VERSION ""

NS_ :

BS_:

BU_: GW OBD

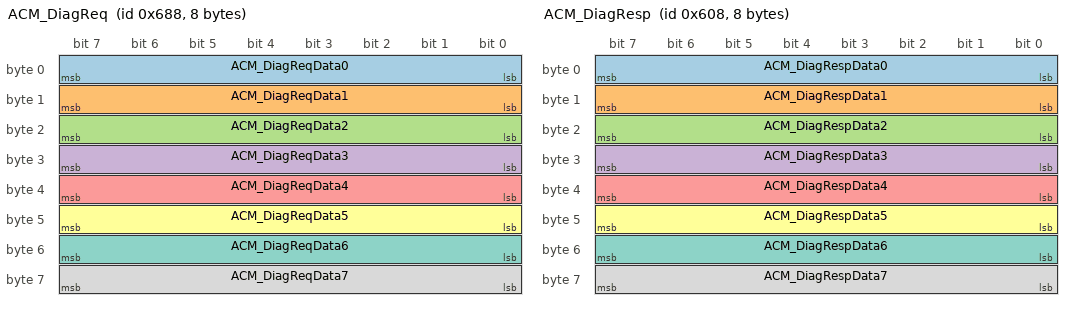
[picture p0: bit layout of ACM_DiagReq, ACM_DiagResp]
BO_ 1672 ACM_DiagReq: 8 OBD
 SG_ ACM_DiagReqData0 : 7|8@0+ (1,0) [0|255] "" GW
 SG_ ACM_DiagReqData1 : 15|8@0+ (1,0) [0|255] "" GW
 SG_ ACM_DiagReqData2 : 23|8@0+ (1,0) [0|255] "" GW
 SG_ ACM_DiagReqData3 : 31|8@0+ (1,0) [0|255] "" GW
 SG_ ACM_DiagReqData4 : 39|8@0+ (1,0) [0|255] "" GW
 SG_ ACM_DiagReqData5 : 47|8@0+ (1,0) [0|255] "" GW
 SG_ ACM_DiagReqData6 : 55|8@0+ (1,0) [0|255] "" GW
 SG_ ACM_DiagReqData7 : 63|8@0+ (1,0) [0|255] "" GW
BO_ 1544 ACM_DiagResp: 8 GW
 SG_ ACM_DiagRespData0 : 7|8@0+ (1,0) [0|255] "" OBD
 SG_ ACM_DiagRespData1 : 15|8@0+ (1,0) [0|255] "" OBD
 SG_ ACM_DiagRespData2 : 23|8@0+ (1,0) [0|255] "" OBD
 SG_ ACM_DiagRespData3 : 31|8@0+ (1,0) [0|255] "" OBD
 SG_ ACM_DiagRespData4 : 39|8@0+ (1,0) [0|255] "" OBD
 SG_ ACM_DiagRespData5 : 47|8@0+ (1,0) [0|255] "" OBD
 SG_ ACM_DiagRespData6 : 55|8@0+ (1,0) [0|255] "" OBD
 SG_ ACM_DiagRespData7 : 63|8@0+ (1,0) [0|255] "" OBD
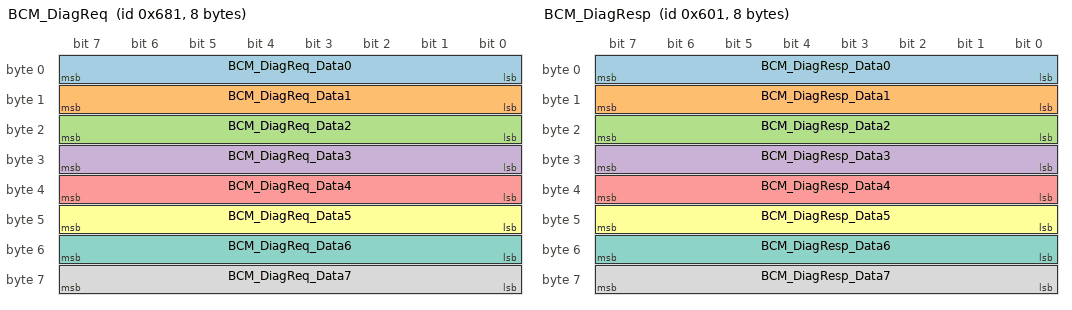
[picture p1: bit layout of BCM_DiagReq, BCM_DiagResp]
BO_ 1665 BCM_DiagReq: 8 OBD
 SG_ BCM_DiagReq_Data0 : 7|8@0+ (1,0) [0|255] "" GW
 SG_ BCM_DiagReq_Data1 : 15|8@0+ (1,0) [0|255] "" GW
 SG_ BCM_DiagReq_Data2 : 23|8@0+ (1,0) [0|255] "" GW
 SG_ BCM_DiagReq_Data3 : 31|8@0+ (1,0) [0|255] "" GW
 SG_ BCM_DiagReq_Data4 : 39|8@0+ (1,0) [0|255] "" GW
 SG_ BCM_DiagReq_Data5 : 47|8@0+ (1,0) [0|255] "" GW
 SG_ BCM_DiagReq_Data6 : 55|8@0+ (1,0) [0|255] "" GW
 SG_ BCM_DiagReq_Data7 : 63|8@0+ (1,0) [0|255] "" GW
BO_ 1537 BCM_DiagResp: 8 GW
 SG_ BCM_DiagResp_Data0 : 7|8@0+ (1,0) [0|255] "" OBD
 SG_ BCM_DiagResp_Data1 : 15|8@0+ (1,0) [0|255] "" OBD
 SG_ BCM_DiagResp_Data2 : 23|8@0+ (1,0) [0|255] "" OBD
 SG_ BCM_DiagResp_Data3 : 31|8@0+ (1,0) [0|255] "" OBD
 SG_ BCM_DiagResp_Data4 : 39|8@0+ (1,0) [0|255] "" OBD
 SG_ BCM_DiagResp_Data5 : 47|8@0+ (1,0) [0|255] "" OBD
 SG_ BCM_DiagResp_Data6 : 55|8@0+ (1,0) [0|255] "" OBD
 SG_ BCM_DiagResp_Data7 : 63|8@0+ (1,0) [0|255] "" OBD
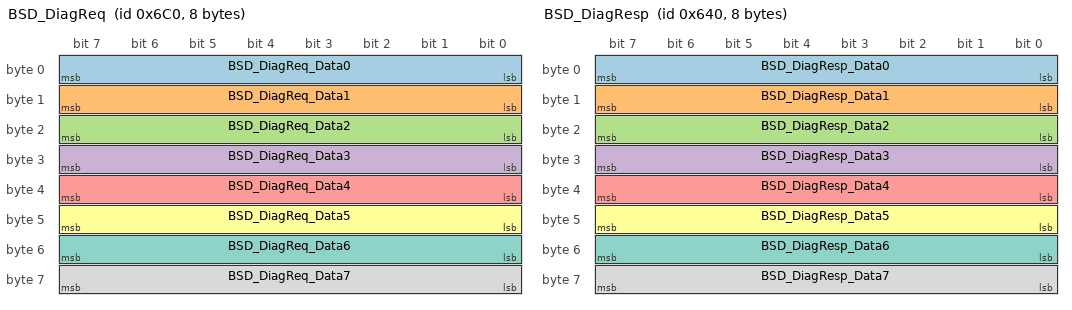
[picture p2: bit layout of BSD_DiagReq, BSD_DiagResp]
BO_ 1728 BSD_DiagReq: 8 OBD
 SG_ BSD_DiagReq_Data0 : 7|8@0+ (1,0) [0|255] "" GW
 SG_ BSD_DiagReq_Data1 : 15|8@0+ (1,0) [0|255] "" GW
 SG_ BSD_DiagReq_Data2 : 23|8@0+ (1,0) [0|255] "" GW
 SG_ BSD_DiagReq_Data3 : 31|8@0+ (1,0) [0|255] "" GW
 SG_ BSD_DiagReq_Data4 : 39|8@0+ (1,0) [0|255] "" GW
 SG_ BSD_DiagReq_Data5 : 47|8@0+ (1,0) [0|255] "" GW
 SG_ BSD_DiagReq_Data6 : 55|8@0+ (1,0) [0|255] "" GW
 SG_ BSD_DiagReq_Data7 : 63|8@0+ (1,0) [0|255] "" GW
BO_ 1600 BSD_DiagResp: 8 GW
 SG_ BSD_DiagResp_Data0 : 7|8@0+ (1,0) [0|255] "" OBD
 SG_ BSD_DiagResp_Data1 : 15|8@0+ (1,0) [0|255] "" OBD
 SG_ BSD_DiagResp_Data2 : 23|8@0+ (1,0) [0|255] "" OBD
 SG_ BSD_DiagResp_Data3 : 31|8@0+ (1,0) [0|255] "" OBD
 SG_ BSD_DiagResp_Data4 : 39|8@0+ (1,0) [0|255] "" OBD
 SG_ BSD_DiagResp_Data5 : 47|8@0+ (1,0) [0|255] "" OBD
 SG_ BSD_DiagResp_Data6 : 55|8@0+ (1,0) [0|255] "" OBD
 SG_ BSD_DiagResp_Data7 : 63|8@0+ (1,0) [0|255] "" OBD
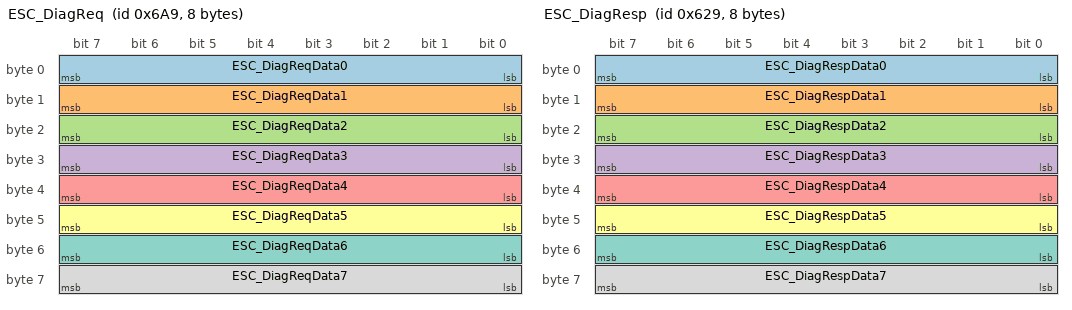
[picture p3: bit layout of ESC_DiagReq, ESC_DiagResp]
BO_ 1705 ESC_DiagReq: 8 OBD
 SG_ ESC_DiagReqData0 : 7|8@0+ (1,0) [0|255] "" GW
 SG_ ESC_DiagReqData1 : 15|8@0+ (1,0) [0|255] "" GW
 SG_ ESC_DiagReqData2 : 23|8@0+ (1,0) [0|255] "" GW
 SG_ ESC_DiagReqData3 : 31|8@0+ (1,0) [0|255] "" GW
 SG_ ESC_DiagReqData4 : 39|8@0+ (1,0) [0|255] "" GW
 SG_ ESC_DiagReqData5 : 47|8@0+ (1,0) [0|255] "" GW
 SG_ ESC_DiagReqData6 : 55|8@0+ (1,0) [0|255] "" GW
 SG_ ESC_DiagReqData7 : 63|8@0+ (1,0) [0|255] "" GW
BO_ 1577 ESC_DiagResp: 8 GW
 SG_ ESC_DiagRespData0 : 7|8@0+ (1,0) [0|255] "" OBD
 SG_ ESC_DiagRespData1 : 15|8@0+ (1,0) [0|255] "" OBD
 SG_ ESC_DiagRespData2 : 23|8@0+ (1,0) [0|255] "" OBD
 SG_ ESC_DiagRespData3 : 31|8@0+ (1,0) [0|255] "" OBD
 SG_ ESC_DiagRespData4 : 39|8@0+ (1,0) [0|255] "" OBD
 SG_ ESC_DiagRespData5 : 47|8@0+ (1,0) [0|255] "" OBD
 SG_ ESC_DiagRespData6 : 55|8@0+ (1,0) [0|255] "" OBD
 SG_ ESC_DiagRespData7 : 63|8@0+ (1,0) [0|255] "" OBD
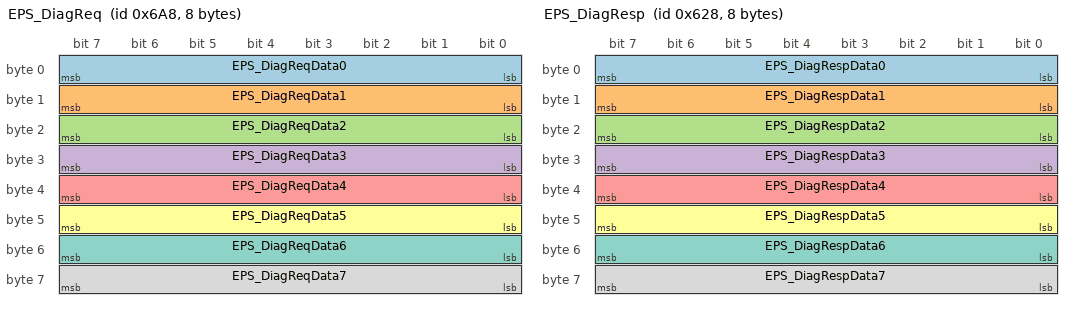
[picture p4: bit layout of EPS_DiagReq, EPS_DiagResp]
BO_ 1704 EPS_DiagReq: 8 OBD
 SG_ EPS_DiagReqData0 : 7|8@0+ (1,0) [0|255] "" GW
 SG_ EPS_DiagReqData1 : 15|8@0+ (1,0) [0|255] "" GW
 SG_ EPS_DiagReqData2 : 23|8@0+ (1,0) [0|255] "" GW
 SG_ EPS_DiagReqData3 : 31|8@0+ (1,0) [0|255] "" GW
 SG_ EPS_DiagReqData4 : 39|8@0+ (1,0) [0|255] "" GW
 SG_ EPS_DiagReqData5 : 47|8@0+ (1,0) [0|255] "" GW
 SG_ EPS_DiagReqData6 : 55|8@0+ (1,0) [0|255] "" GW
 SG_ EPS_DiagReqData7 : 63|8@0+ (1,0) [0|255] "" GW
BO_ 1576 EPS_DiagResp: 8 GW
 SG_ EPS_DiagRespData0 : 7|8@0+ (1,0) [0|255] "" OBD
 SG_ EPS_DiagRespData1 : 15|8@0+ (1,0) [0|255] "" OBD
 SG_ EPS_DiagRespData2 : 23|8@0+ (1,0) [0|255] "" OBD
 SG_ EPS_DiagRespData3 : 31|8@0+ (1,0) [0|255] "" OBD
 SG_ EPS_DiagRespData4 : 39|8@0+ (1,0) [0|255] "" OBD
 SG_ EPS_DiagRespData5 : 47|8@0+ (1,0) [0|255] "" OBD
 SG_ EPS_DiagRespData6 : 55|8@0+ (1,0) [0|255] "" OBD
 SG_ EPS_DiagRespData7 : 63|8@0+ (1,0) [0|255] "" OBD
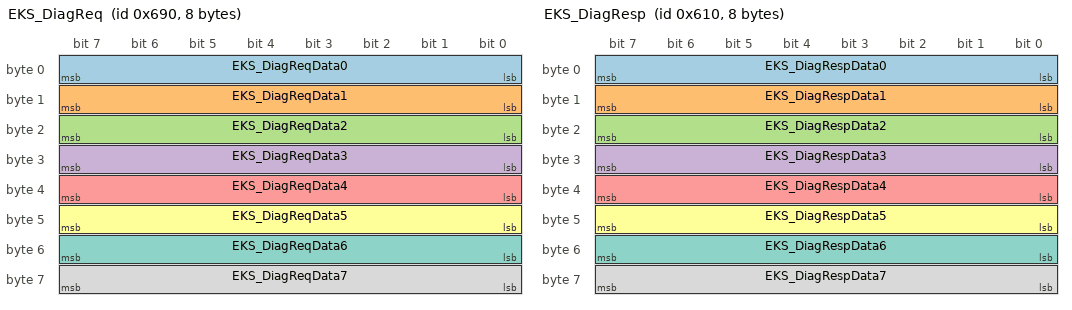
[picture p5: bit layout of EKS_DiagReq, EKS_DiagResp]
BO_ 1680 EKS_DiagReq: 8 OBD
 SG_ EKS_DiagReqData0 : 7|8@0+ (1,0) [0|255] "" GW
 SG_ EKS_DiagReqData1 : 15|8@0+ (1,0) [0|255] "" GW
 SG_ EKS_DiagReqData2 : 23|8@0+ (1,0) [0|255] "" GW
 SG_ EKS_DiagReqData3 : 31|8@0+ (1,0) [0|255] "" GW
 SG_ EKS_DiagReqData4 : 39|8@0+ (1,0) [0|255] "" GW
 SG_ EKS_DiagReqData5 : 47|8@0+ (1,0) [0|255] "" GW
 SG_ EKS_DiagReqData6 : 55|8@0+ (1,0) [0|255] "" GW
 SG_ EKS_DiagReqData7 : 63|8@0+ (1,0) [0|255] "" GW
BO_ 1552 EKS_DiagResp: 8 GW
 SG_ EKS_DiagRespData0 : 7|8@0+ (1,0) [0|255] "" OBD
 SG_ EKS_DiagRespData1 : 15|8@0+ (1,0) [0|255] "" OBD
 SG_ EKS_DiagRespData2 : 23|8@0+ (1,0) [0|255] "" OBD
 SG_ EKS_DiagRespData3 : 31|8@0+ (1,0) [0|255] "" OBD
 SG_ EKS_DiagRespData4 : 39|8@0+ (1,0) [0|255] "" OBD
 SG_ EKS_DiagRespData5 : 47|8@0+ (1,0) [0|255] "" OBD
 SG_ EKS_DiagRespData6 : 55|8@0+ (1,0) [0|255] "" OBD
 SG_ EKS_DiagRespData7 : 63|8@0+ (1,0) [0|255] "" OBD
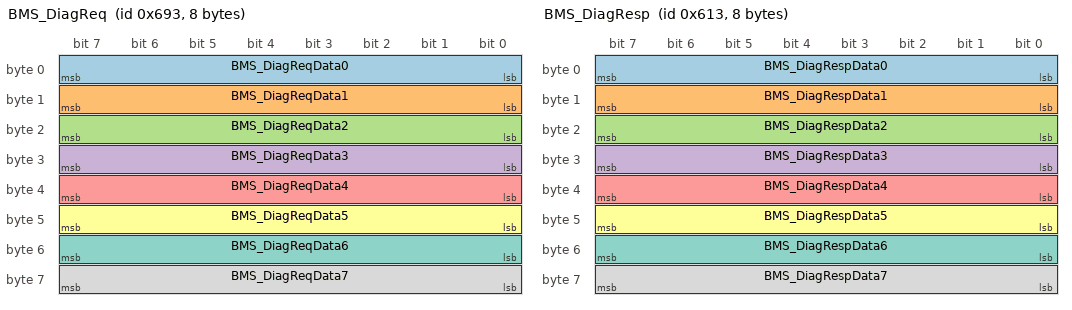
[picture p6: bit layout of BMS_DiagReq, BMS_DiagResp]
BO_ 1683 BMS_DiagReq: 8 OBD
 SG_ BMS_DiagReqData0 : 7|8@0+ (1,0) [0|255] "" GW
 SG_ BMS_DiagReqData1 : 15|8@0+ (1,0) [0|255] "" GW
 SG_ BMS_DiagReqData2 : 23|8@0+ (1,0) [0|255] "" GW
 SG_ BMS_DiagReqData3 : 31|8@0+ (1,0) [0|255] "" GW
 SG_ BMS_DiagReqData4 : 39|8@0+ (1,0) [0|255] "" GW
 SG_ BMS_DiagReqData5 : 47|8@0+ (1,0) [0|255] "" GW
 SG_ BMS_DiagReqData6 : 55|8@0+ (1,0) [0|255] "" GW
 SG_ BMS_DiagReqData7 : 63|8@0+ (1,0) [0|255] "" GW
BO_ 1555 BMS_DiagResp: 8 GW
 SG_ BMS_DiagRespData0 : 7|8@0+ (1,0) [0|255] "" OBD
 SG_ BMS_DiagRespData1 : 15|8@0+ (1,0) [0|255] "" OBD
 SG_ BMS_DiagRespData2 : 23|8@0+ (1,0) [0|255] "" OBD
 SG_ BMS_DiagRespData3 : 31|8@0+ (1,0) [0|255] "" OBD
 SG_ BMS_DiagRespData4 : 39|8@0+ (1,0) [0|255] "" OBD
 SG_ BMS_DiagRespData5 : 47|8@0+ (1,0) [0|255] "" OBD
 SG_ BMS_DiagRespData6 : 55|8@0+ (1,0) [0|255] "" OBD
 SG_ BMS_DiagRespData7 : 63|8@0+ (1,0) [0|255] "" OBD
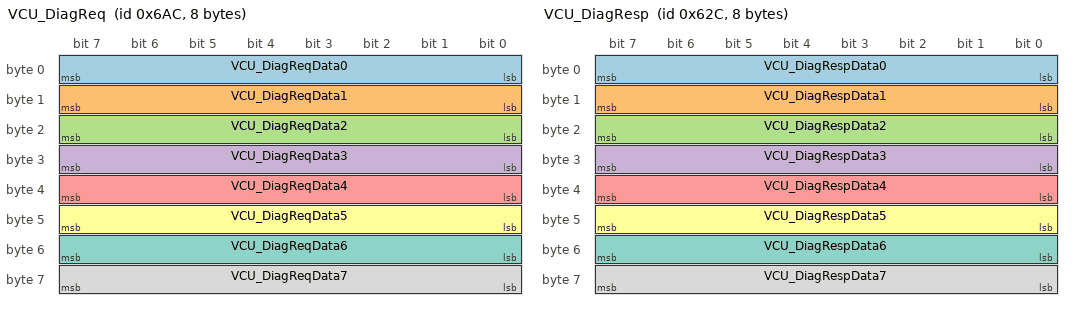
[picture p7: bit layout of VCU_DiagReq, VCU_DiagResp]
BO_ 1708 VCU_DiagReq: 8 OBD
 SG_ VCU_DiagReqData0 : 7|8@0+ (1,0) [0|255] "" GW
 SG_ VCU_DiagReqData1 : 15|8@0+ (1,0) [0|255] "" GW
 SG_ VCU_DiagReqData2 : 23|8@0+ (1,0) [0|255] "" GW
 SG_ VCU_DiagReqData3 : 31|8@0+ (1,0) [0|255] "" GW
 SG_ VCU_DiagReqData4 : 39|8@0+ (1,0) [0|255] "" GW
 SG_ VCU_DiagReqData5 : 47|8@0+ (1,0) [0|255] "" GW
 SG_ VCU_DiagReqData6 : 55|8@0+ (1,0) [0|255] "" GW
 SG_ VCU_DiagReqData7 : 63|8@0+ (1,0) [0|255] "" GW
BO_ 1580 VCU_DiagResp: 8 GW
 SG_ VCU_DiagRespData0 : 7|8@0+ (1,0) [0|255] "" OBD
 SG_ VCU_DiagRespData1 : 15|8@0+ (1,0) [0|255] "" OBD
 SG_ VCU_DiagRespData2 : 23|8@0+ (1,0) [0|255] "" OBD
 SG_ VCU_DiagRespData3 : 31|8@0+ (1,0) [0|255] "" OBD
 SG_ VCU_DiagRespData4 : 39|8@0+ (1,0) [0|255] "" OBD
 SG_ VCU_DiagRespData5 : 47|8@0+ (1,0) [0|255] "" OBD
 SG_ VCU_DiagRespData6 : 55|8@0+ (1,0) [0|255] "" OBD
 SG_ VCU_DiagRespData7 : 63|8@0+ (1,0) [0|255] "" OBD
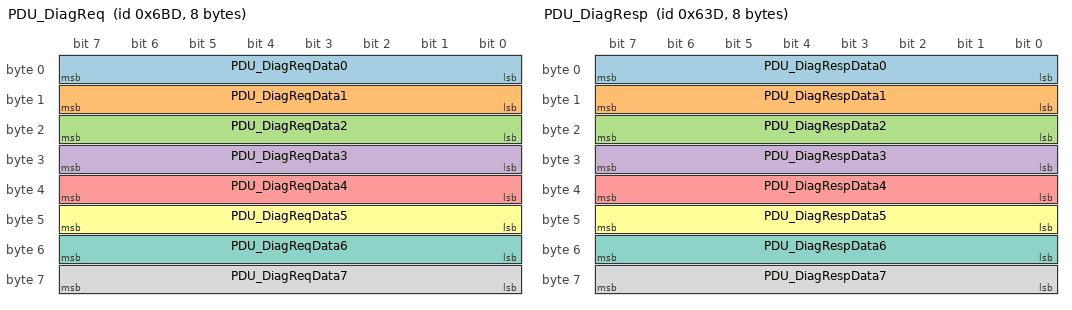
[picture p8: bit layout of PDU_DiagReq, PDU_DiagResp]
BO_ 1725 PDU_DiagReq: 8 OBD
 SG_ PDU_DiagReqData0 : 7|8@0+ (1,0) [0|255] "" GW
 SG_ PDU_DiagReqData1 : 15|8@0+ (1,0) [0|255] "" GW
 SG_ PDU_DiagReqData2 : 23|8@0+ (1,0) [0|255] "" GW
 SG_ PDU_DiagReqData3 : 31|8@0+ (1,0) [0|255] "" GW
 SG_ PDU_DiagReqData4 : 39|8@0+ (1,0) [0|255] "" GW
 SG_ PDU_DiagReqData5 : 47|8@0+ (1,0) [0|255] "" GW
 SG_ PDU_DiagReqData6 : 55|8@0+ (1,0) [0|255] "" GW
 SG_ PDU_DiagReqData7 : 63|8@0+ (1,0) [0|255] "" GW
BO_ 1597 PDU_DiagResp: 8 GW
 SG_ PDU_DiagRespData0 : 7|8@0+ (1,0) [0|255] "" OBD
 SG_ PDU_DiagRespData1 : 15|8@0+ (1,0) [0|255] "" OBD
 SG_ PDU_DiagRespData2 : 23|8@0+ (1,0) [0|255] "" OBD
 SG_ PDU_DiagRespData3 : 31|8@0+ (1,0) [0|255] "" OBD
 SG_ PDU_DiagRespData4 : 39|8@0+ (1,0) [0|255] "" OBD
 SG_ PDU_DiagRespData5 : 47|8@0+ (1,0) [0|255] "" OBD
 SG_ PDU_DiagRespData6 : 55|8@0+ (1,0) [0|255] "" OBD
 SG_ PDU_DiagRespData7 : 63|8@0+ (1,0) [0|255] "" OBD
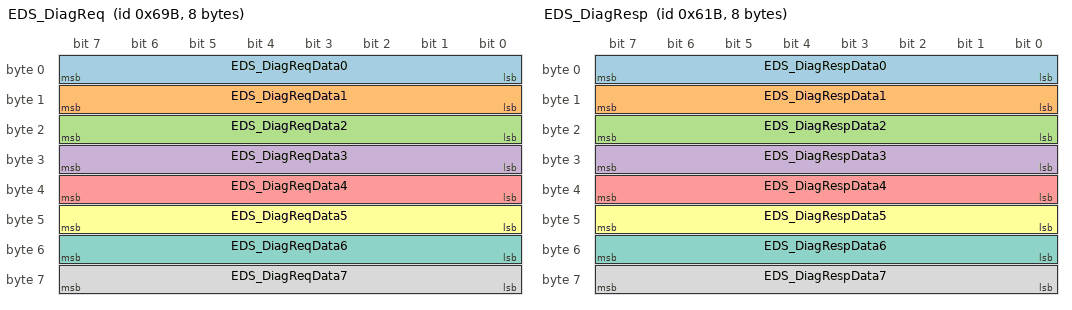
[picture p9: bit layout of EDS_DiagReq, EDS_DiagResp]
BO_ 1691 EDS_DiagReq: 8 OBD
 SG_ EDS_DiagReqData0 : 7|8@0+ (1,0) [0|255] "" GW
 SG_ EDS_DiagReqData1 : 15|8@0+ (1,0) [0|255] "" GW
 SG_ EDS_DiagReqData2 : 23|8@0+ (1,0) [0|255] "" GW
 SG_ EDS_DiagReqData3 : 31|8@0+ (1,0) [0|255] "" GW
 SG_ EDS_DiagReqData4 : 39|8@0+ (1,0) [0|255] "" GW
 SG_ EDS_DiagReqData5 : 47|8@0+ (1,0) [0|255] "" GW
 SG_ EDS_DiagReqData6 : 55|8@0+ (1,0) [0|255] "" GW
 SG_ EDS_DiagReqData7 : 63|8@0+ (1,0) [0|255] "" GW
BO_ 1563 EDS_DiagResp: 8 GW
 SG_ EDS_DiagRespData0 : 7|8@0+ (1,0) [0|255] "" OBD
 SG_ EDS_DiagRespData1 : 15|8@0+ (1,0) [0|255] "" OBD
 SG_ EDS_DiagRespData2 : 23|8@0+ (1,0) [0|255] "" OBD
 SG_ EDS_DiagRespData3 : 31|8@0+ (1,0) [0|255] "" OBD
 SG_ EDS_DiagRespData4 : 39|8@0+ (1,0) [0|255] "" OBD
 SG_ EDS_DiagRespData5 : 47|8@0+ (1,0) [0|255] "" OBD
 SG_ EDS_DiagRespData6 : 55|8@0+ (1,0) [0|255] "" OBD
 SG_ EDS_DiagRespData7 : 63|8@0+ (1,0) [0|255] "" OBD
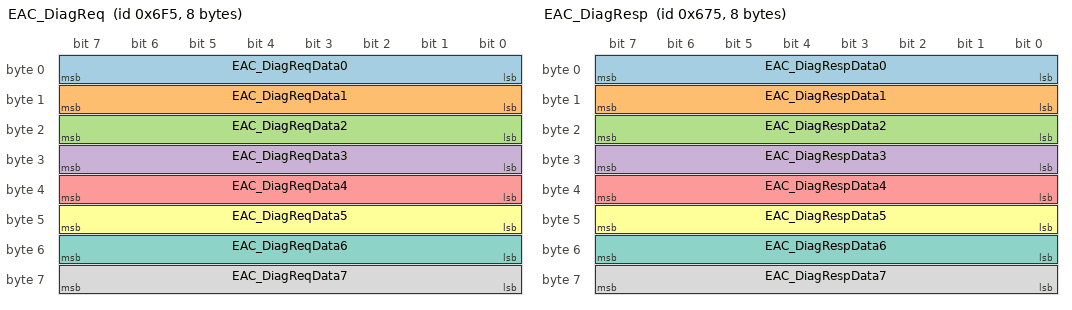
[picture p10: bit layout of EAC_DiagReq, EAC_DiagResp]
BO_ 1781 EAC_DiagReq: 8 OBD
 SG_ EAC_DiagReqData0 : 7|8@0+ (1,0) [0|255] "" GW
 SG_ EAC_DiagReqData1 : 15|8@0+ (1,0) [0|255] "" GW
 SG_ EAC_DiagReqData2 : 23|8@0+ (1,0) [0|255] "" GW
 SG_ EAC_DiagReqData3 : 31|8@0+ (1,0) [0|255] "" GW
 SG_ EAC_DiagReqData4 : 39|8@0+ (1,0) [0|255] "" GW
 SG_ EAC_DiagReqData5 : 47|8@0+ (1,0) [0|255] "" GW
 SG_ EAC_DiagReqData6 : 55|8@0+ (1,0) [0|255] "" GW
 SG_ EAC_DiagReqData7 : 63|8@0+ (1,0) [0|255] "" GW
BO_ 1653 EAC_DiagResp: 8 GW
 SG_ EAC_DiagRespData0 : 7|8@0+ (1,0) [0|255] "" OBD
 SG_ EAC_DiagRespData1 : 15|8@0+ (1,0) [0|255] "" OBD
 SG_ EAC_DiagRespData2 : 23|8@0+ (1,0) [0|255] "" OBD
 SG_ EAC_DiagRespData3 : 31|8@0+ (1,0) [0|255] "" OBD
 SG_ EAC_DiagRespData4 : 39|8@0+ (1,0) [0|255] "" OBD
 SG_ EAC_DiagRespData5 : 47|8@0+ (1,0) [0|255] "" OBD
 SG_ EAC_DiagRespData6 : 55|8@0+ (1,0) [0|255] "" OBD
 SG_ EAC_DiagRespData7 : 63|8@0+ (1,0) [0|255] "" OBD
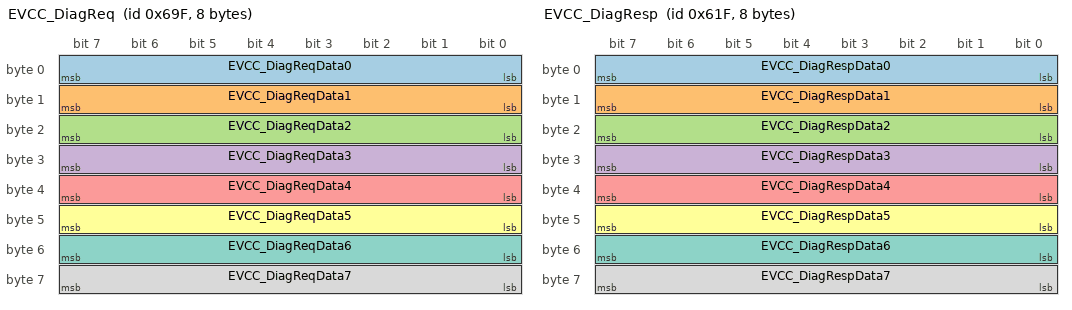
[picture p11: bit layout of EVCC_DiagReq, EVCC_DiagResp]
BO_ 1695 EVCC_DiagReq: 8 OBD
 SG_ EVCC_DiagReqData0 : 7|8@0+ (1,0) [0|255] "" GW
 SG_ EVCC_DiagReqData1 : 15|8@0+ (1,0) [0|255] "" GW
 SG_ EVCC_DiagReqData2 : 23|8@0+ (1,0) [0|255] "" GW
 SG_ EVCC_DiagReqData3 : 31|8@0+ (1,0) [0|255] "" GW
 SG_ EVCC_DiagReqData4 : 39|8@0+ (1,0) [0|255] "" GW
 SG_ EVCC_DiagReqData5 : 47|8@0+ (1,0) [0|255] "" GW
 SG_ EVCC_DiagReqData6 : 55|8@0+ (1,0) [0|255] "" GW
 SG_ EVCC_DiagReqData7 : 63|8@0+ (1,0) [0|255] "" GW
BO_ 1567 EVCC_DiagResp: 8 GW
 SG_ EVCC_DiagRespData0 : 7|8@0+ (1,0) [0|255] "" OBD
 SG_ EVCC_DiagRespData1 : 15|8@0+ (1,0) [0|255] "" OBD
 SG_ EVCC_DiagRespData2 : 23|8@0+ (1,0) [0|255] "" OBD
 SG_ EVCC_DiagRespData3 : 31|8@0+ (1,0) [0|255] "" OBD
 SG_ EVCC_DiagRespData4 : 39|8@0+ (1,0) [0|255] "" OBD
 SG_ EVCC_DiagRespData5 : 47|8@0+ (1,0) [0|255] "" OBD
 SG_ EVCC_DiagRespData6 : 55|8@0+ (1,0) [0|255] "" OBD
 SG_ EVCC_DiagRespData7 : 63|8@0+ (1,0) [0|255] "" OBD
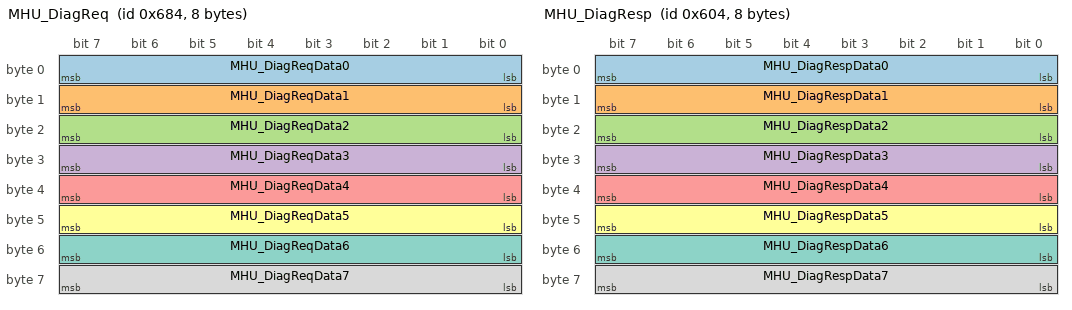
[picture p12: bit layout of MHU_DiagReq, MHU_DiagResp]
BO_ 1668 MHU_DiagReq: 8 OBD
 SG_ MHU_DiagReqData0 : 7|8@0+ (1,0) [0|255] "" GW
 SG_ MHU_DiagReqData1 : 15|8@0+ (1,0) [0|255] "" GW
 SG_ MHU_DiagReqData2 : 23|8@0+ (1,0) [0|255] "" GW
 SG_ MHU_DiagReqData3 : 31|8@0+ (1,0) [0|255] "" GW
 SG_ MHU_DiagReqData4 : 39|8@0+ (1,0) [0|255] "" GW
 SG_ MHU_DiagReqData5 : 47|8@0+ (1,0) [0|255] "" GW
 SG_ MHU_DiagReqData6 : 55|8@0+ (1,0) [0|255] "" GW
 SG_ MHU_DiagReqData7 : 63|8@0+ (1,0) [0|255] "" GW
BO_ 1540 MHU_DiagResp: 8 GW
 SG_ MHU_DiagRespData0 : 7|8@0+ (1,0) [0|255] "" OBD
 SG_ MHU_DiagRespData1 : 15|8@0+ (1,0) [0|255] "" OBD
 SG_ MHU_DiagRespData2 : 23|8@0+ (1,0) [0|255] "" OBD
 SG_ MHU_DiagRespData3 : 31|8@0+ (1,0) [0|255] "" OBD
 SG_ MHU_DiagRespData4 : 39|8@0+ (1,0) [0|255] "" OBD
 SG_ MHU_DiagRespData5 : 47|8@0+ (1,0) [0|255] "" OBD
 SG_ MHU_DiagRespData6 : 55|8@0+ (1,0) [0|255] "" OBD
 SG_ MHU_DiagRespData7 : 63|8@0+ (1,0) [0|255] "" OBD
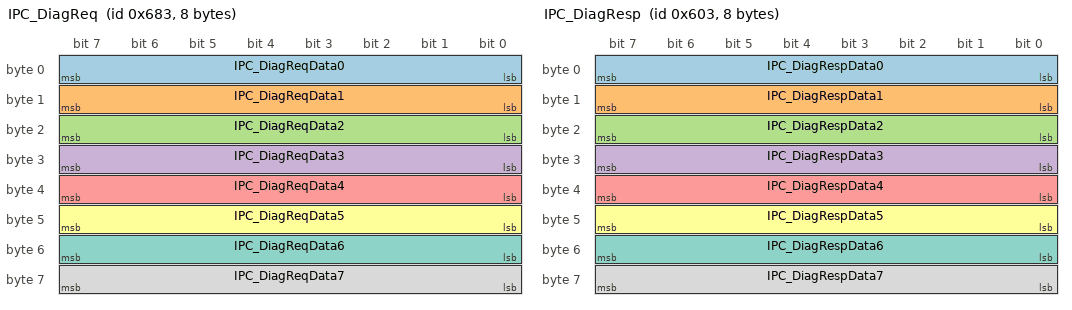
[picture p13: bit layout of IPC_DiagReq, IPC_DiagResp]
BO_ 1667 IPC_DiagReq: 8 OBD
 SG_ IPC_DiagReqData0 : 7|8@0+ (1,0) [0|255] "" GW
 SG_ IPC_DiagReqData1 : 15|8@0+ (1,0) [0|255] "" GW
 SG_ IPC_DiagReqData2 : 23|8@0+ (1,0) [0|255] "" GW
 SG_ IPC_DiagReqData3 : 31|8@0+ (1,0) [0|255] "" GW
 SG_ IPC_DiagReqData4 : 39|8@0+ (1,0) [0|255] "" GW
 SG_ IPC_DiagReqData5 : 47|8@0+ (1,0) [0|255] "" GW
 SG_ IPC_DiagReqData6 : 55|8@0+ (1,0) [0|255] "" GW
 SG_ IPC_DiagReqData7 : 63|8@0+ (1,0) [0|255] "" GW
BO_ 1539 IPC_DiagResp: 8 GW
 SG_ IPC_DiagRespData0 : 7|8@0+ (1,0) [0|255] "" OBD
 SG_ IPC_DiagRespData1 : 15|8@0+ (1,0) [0|255] "" OBD
 SG_ IPC_DiagRespData2 : 23|8@0+ (1,0) [0|255] "" OBD
 SG_ IPC_DiagRespData3 : 31|8@0+ (1,0) [0|255] "" OBD
 SG_ IPC_DiagRespData4 : 39|8@0+ (1,0) [0|255] "" OBD
 SG_ IPC_DiagRespData5 : 47|8@0+ (1,0) [0|255] "" OBD
 SG_ IPC_DiagRespData6 : 55|8@0+ (1,0) [0|255] "" OBD
 SG_ IPC_DiagRespData7 : 63|8@0+ (1,0) [0|255] "" OBD
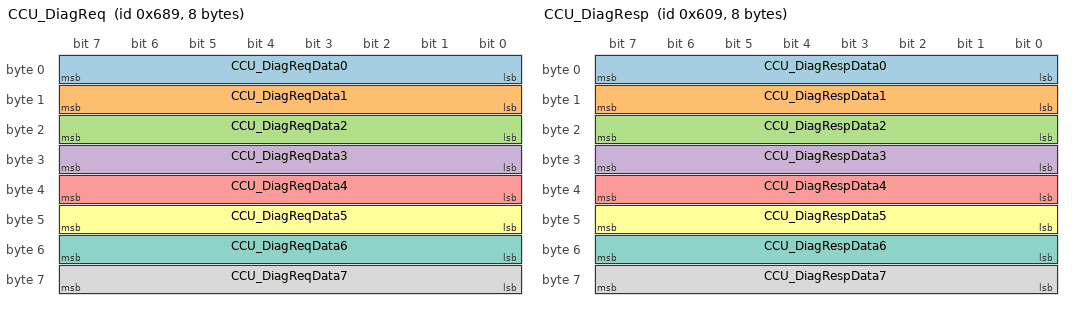
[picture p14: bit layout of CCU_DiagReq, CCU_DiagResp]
BO_ 1673 CCU_DiagReq: 8 OBD
 SG_ CCU_DiagReqData0 : 7|8@0+ (1,0) [0|255] "" GW
 SG_ CCU_DiagReqData1 : 15|8@0+ (1,0) [0|255] "" GW
 SG_ CCU_DiagReqData2 : 23|8@0+ (1,0) [0|255] "" GW
 SG_ CCU_DiagReqData3 : 31|8@0+ (1,0) [0|255] "" GW
 SG_ CCU_DiagReqData4 : 39|8@0+ (1,0) [0|255] "" GW
 SG_ CCU_DiagReqData5 : 47|8@0+ (1,0) [0|255] "" GW
 SG_ CCU_DiagReqData6 : 55|8@0+ (1,0) [0|255] "" GW
 SG_ CCU_DiagReqData7 : 63|8@0+ (1,0) [0|255] "" GW
BO_ 1545 CCU_DiagResp: 8 GW
 SG_ CCU_DiagRespData0 : 7|8@0+ (1,0) [0|255] "" OBD
 SG_ CCU_DiagRespData1 : 15|8@0+ (1,0) [0|255] "" OBD
 SG_ CCU_DiagRespData2 : 23|8@0+ (1,0) [0|255] "" OBD
 SG_ CCU_DiagRespData3 : 31|8@0+ (1,0) [0|255] "" OBD
 SG_ CCU_DiagRespData4 : 39|8@0+ (1,0) [0|255] "" OBD
 SG_ CCU_DiagRespData5 : 47|8@0+ (1,0) [0|255] "" OBD
 SG_ CCU_DiagRespData6 : 55|8@0+ (1,0) [0|255] "" OBD
 SG_ CCU_DiagRespData7 : 63|8@0+ (1,0) [0|255] "" OBD
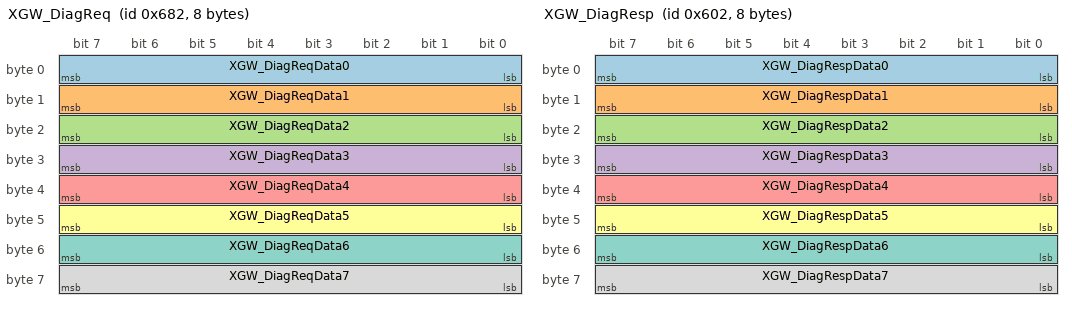
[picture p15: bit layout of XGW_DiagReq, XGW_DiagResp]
BO_ 1666 XGW_DiagReq: 8 OBD
 SG_ XGW_DiagReqData0 : 7|8@0+ (1,0) [0|255] "" GW
 SG_ XGW_DiagReqData1 : 15|8@0+ (1,0) [0|255] "" GW
 SG_ XGW_DiagReqData2 : 23|8@0+ (1,0) [0|255] "" GW
 SG_ XGW_DiagReqData3 : 31|8@0+ (1,0) [0|255] "" GW
 SG_ XGW_DiagReqData4 : 39|8@0+ (1,0) [0|255] "" GW
 SG_ XGW_DiagReqData5 : 47|8@0+ (1,0) [0|255] "" GW
 SG_ XGW_DiagReqData6 : 55|8@0+ (1,0) [0|255] "" GW
 SG_ XGW_DiagReqData7 : 63|8@0+ (1,0) [0|255] "" GW
BO_ 1538 XGW_DiagResp: 8 GW
 SG_ XGW_DiagRespData0 : 7|8@0+ (1,0) [0|255] "" OBD
 SG_ XGW_DiagRespData1 : 15|8@0+ (1,0) [0|255] "" OBD
 SG_ XGW_DiagRespData2 : 23|8@0+ (1,0) [0|255] "" OBD
 SG_ XGW_DiagRespData3 : 31|8@0+ (1,0) [0|255] "" OBD
 SG_ XGW_DiagRespData4 : 39|8@0+ (1,0) [0|255] "" OBD
 SG_ XGW_DiagRespData5 : 47|8@0+ (1,0) [0|255] "" OBD
 SG_ XGW_DiagRespData6 : 55|8@0+ (1,0) [0|255] "" OBD
 SG_ XGW_DiagRespData7 : 63|8@0+ (1,0) [0|255] "" OBD
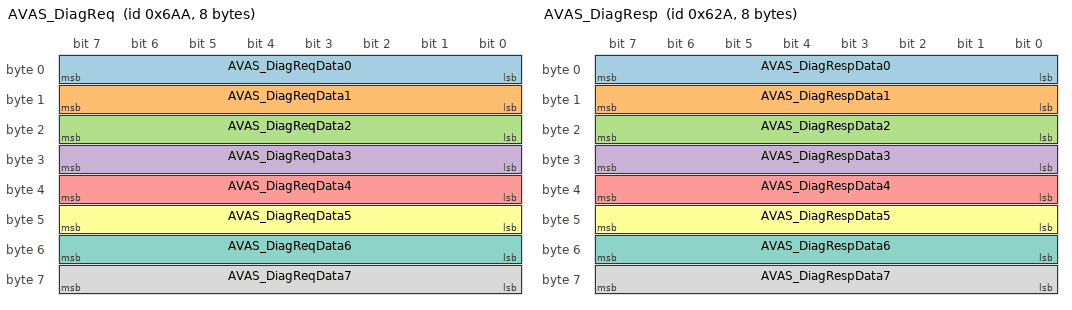
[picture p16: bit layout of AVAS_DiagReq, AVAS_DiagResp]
BO_ 1706 AVAS_DiagReq: 8 OBD
 SG_ AVAS_DiagReqData0 : 7|8@0+ (1,0) [0|255] "" GW
 SG_ AVAS_DiagReqData1 : 15|8@0+ (1,0) [0|255] "" GW
 SG_ AVAS_DiagReqData2 : 23|8@0+ (1,0) [0|255] "" GW
 SG_ AVAS_DiagReqData3 : 31|8@0+ (1,0) [0|255] "" GW
 SG_ AVAS_DiagReqData4 : 39|8@0+ (1,0) [0|255] "" GW
 SG_ AVAS_DiagReqData5 : 47|8@0+ (1,0) [0|255] "" GW
 SG_ AVAS_DiagReqData6 : 55|8@0+ (1,0) [0|255] "" GW
 SG_ AVAS_DiagReqData7 : 63|8@0+ (1,0) [0|255] "" GW
BO_ 1578 AVAS_DiagResp: 8 GW
 SG_ AVAS_DiagRespData0 : 7|8@0+ (1,0) [0|255] "" OBD
 SG_ AVAS_DiagRespData1 : 15|8@0+ (1,0) [0|255] "" OBD
 SG_ AVAS_DiagRespData2 : 23|8@0+ (1,0) [0|255] "" OBD
 SG_ AVAS_DiagRespData3 : 31|8@0+ (1,0) [0|255] "" OBD
 SG_ AVAS_DiagRespData4 : 39|8@0+ (1,0) [0|255] "" OBD
 SG_ AVAS_DiagRespData5 : 47|8@0+ (1,0) [0|255] "" OBD
 SG_ AVAS_DiagRespData6 : 55|8@0+ (1,0) [0|255] "" OBD
 SG_ AVAS_DiagRespData7 : 63|8@0+ (1,0) [0|255] "" OBD
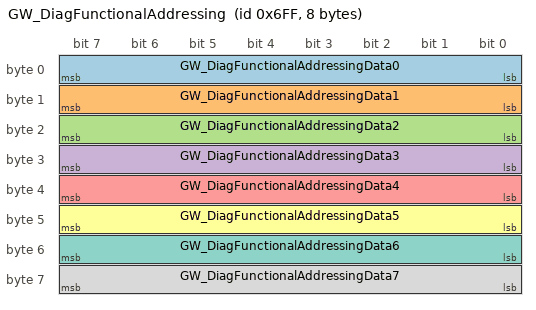
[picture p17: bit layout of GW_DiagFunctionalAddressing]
BO_ 1791 GW_DiagFunctionalAddressing: 8 OBD
 SG_ GW_DiagFunctionalAddressingData0 : 7|8@0+ (1,0) [0|255] "" GW
 SG_ GW_DiagFunctionalAddressingData1 : 15|8@0+ (1,0) [0|255] "" GW
 SG_ GW_DiagFunctionalAddressingData2 : 23|8@0+ (1,0) [0|255] "" GW
 SG_ GW_DiagFunctionalAddressingData3 : 31|8@0+ (1,0) [0|255] "" GW
 SG_ GW_DiagFunctionalAddressingData4 : 39|8@0+ (1,0) [0|255] "" GW
 SG_ GW_DiagFunctionalAddressingData5 : 47|8@0+ (1,0) [0|255] "" GW
 SG_ GW_DiagFunctionalAddressingData6 : 55|8@0+ (1,0) [0|255] "" GW
 SG_ GW_DiagFunctionalAddressingData7 : 63|8@0+ (1,0) [0|255] "" GW
CM_ SG_ 1672 ACM_DiagReqData0 "Data0";
CM_ SG_ 1672 ACM_DiagReqData1 "Data1";
CM_ SG_ 1672 ACM_DiagReqData2 "Data2";
CM_ SG_ 1672 ACM_DiagReqData3 "Data3";
CM_ SG_ 1672 ACM_DiagReqData4 "Data4";
CM_ SG_ 1672 ACM_DiagReqData5 "Data5";
CM_ SG_ 1672 ACM_DiagReqData6 "Data6";
CM_ SG_ 1672 ACM_DiagReqData7 "Data7";
CM_ SG_ 1544 ACM_DiagRespData0 "Data0";
CM_ SG_ 1544 ACM_DiagRespData1 "Data1";
CM_ SG_ 1544 ACM_DiagRespData2 "Data2";
CM_ SG_ 1544 ACM_DiagRespData3 "Data3";
CM_ SG_ 1544 ACM_DiagRespData4 "Data4";
CM_ SG_ 1544 ACM_DiagRespData5 "Data5";
CM_ SG_ 1544 ACM_DiagRespData6 "Data6";
CM_ SG_ 1544 ACM_DiagRespData7 "Data7";
CM_ SG_ 1665 BCM_DiagReq_Data0 "Data0";
CM_ SG_ 1665 BCM_DiagReq_Data1 "Data1";
CM_ SG_ 1665 BCM_DiagReq_Data2 "Data2";
CM_ SG_ 1665 BCM_DiagReq_Data3 "Data3";
CM_ SG_ 1665 BCM_DiagReq_Data4 "Data4";
CM_ SG_ 1665 BCM_DiagReq_Data5 "Data5";
CM_ SG_ 1665 BCM_DiagReq_Data6 "Data6";
CM_ SG_ 1665 BCM_DiagReq_Data7 "Data7";
CM_ SG_ 1537 BCM_DiagResp_Data0 "Data0";
CM_ SG_ 1537 BCM_DiagResp_Data1 "Data1";
CM_ SG_ 1537 BCM_DiagResp_Data2 "Data2";
CM_ SG_ 1537 BCM_DiagResp_Data3 "Data3";
CM_ SG_ 1537 BCM_DiagResp_Data4 "Data4";
CM_ SG_ 1537 BCM_DiagResp_Data5 "Data5";
CM_ SG_ 1537 BCM_DiagResp_Data6 "Data6";
CM_ SG_ 1537 BCM_DiagResp_Data7 "Data7";
CM_ SG_ 1728 BSD_DiagReq_Data0 "Data0";
CM_ SG_ 1728 BSD_DiagReq_Data1 "Data1";
CM_ SG_ 1728 BSD_DiagReq_Data2 "Data2";
CM_ SG_ 1728 BSD_DiagReq_Data3 "Data3";
CM_ SG_ 1728 BSD_DiagReq_Data4 "Data4";
CM_ SG_ 1728 BSD_DiagReq_Data5 "Data5";
CM_ SG_ 1728 BSD_DiagReq_Data6 "Data6";
CM_ SG_ 1728 BSD_DiagReq_Data7 "Data7";
CM_ SG_ 1600 BSD_DiagResp_Data0 "Data0";
CM_ SG_ 1600 BSD_DiagResp_Data1 "Data1";
CM_ SG_ 1600 BSD_DiagResp_Data2 "Data2";
CM_ SG_ 1600 BSD_DiagResp_Data3 "Data3";
CM_ SG_ 1600 BSD_DiagResp_Data4 "Data4";
CM_ SG_ 1600 BSD_DiagResp_Data5 "Data5";
CM_ SG_ 1600 BSD_DiagResp_Data6 "Data6";
CM_ SG_ 1600 BSD_DiagResp_Data7 "Data7";
CM_ SG_ 1705 ESC_DiagReqData0 "Data0";
CM_ SG_ 1705 ESC_DiagReqData1 "Data1";
CM_ SG_ 1705 ESC_DiagReqData2 "Data2";
CM_ SG_ 1705 ESC_DiagReqData3 "Data3";
CM_ SG_ 1705 ESC_DiagReqData4 "Data4";
CM_ SG_ 1705 ESC_DiagReqData5 "Data5";
CM_ SG_ 1705 ESC_DiagReqData6 "Data6";
CM_ SG_ 1705 ESC_DiagReqData7 "Data7";
CM_ SG_ 1577 ESC_DiagRespData0 "Data0";
CM_ SG_ 1577 ESC_DiagRespData1 "Data1";
CM_ SG_ 1577 ESC_DiagRespData2 "Data2";
CM_ SG_ 1577 ESC_DiagRespData3 "Data3";
CM_ SG_ 1577 ESC_DiagRespData4 "Data4";
CM_ SG_ 1577 ESC_DiagRespData5 "Data5";
CM_ SG_ 1577 ESC_DiagRespData6 "Data6";
CM_ SG_ 1577 ESC_DiagRespData7 "Data7";
CM_ SG_ 1704 EPS_DiagReqData0 "Data0";
CM_ SG_ 1704 EPS_DiagReqData1 "Data1";
CM_ SG_ 1704 EPS_DiagReqData2 "Data2";
CM_ SG_ 1704 EPS_DiagReqData3 "Data3";
CM_ SG_ 1704 EPS_DiagReqData4 "Data4";
CM_ SG_ 1704 EPS_DiagReqData5 "Data5";
CM_ SG_ 1704 EPS_DiagReqData6 "Data6";
CM_ SG_ 1704 EPS_DiagReqData7 "Data7";
CM_ SG_ 1576 EPS_DiagRespData0 "Data0";
CM_ SG_ 1576 EPS_DiagRespData1 "Data1";
CM_ SG_ 1576 EPS_DiagRespData2 "Data2";
CM_ SG_ 1576 EPS_DiagRespData3 "Data3";
CM_ SG_ 1576 EPS_DiagRespData4 "Data4";
CM_ SG_ 1576 EPS_DiagRespData5 "Data5";
CM_ SG_ 1576 EPS_DiagRespData6 "Data6";
CM_ SG_ 1576 EPS_DiagRespData7 "Data7";
CM_ SG_ 1680 EKS_DiagReqData0 "Data0";
CM_ SG_ 1680 EKS_DiagReqData1 "Data1";
CM_ SG_ 1680 EKS_DiagReqData2 "Data2";
CM_ SG_ 1680 EKS_DiagReqData3 "Data3";
CM_ SG_ 1680 EKS_DiagReqData4 "Data4";
CM_ SG_ 1680 EKS_DiagReqData5 "Data5";
CM_ SG_ 1680 EKS_DiagReqData6 "Data6";
CM_ SG_ 1680 EKS_DiagReqData7 "Data7";
CM_ SG_ 1552 EKS_DiagRespData0 "Data0";
CM_ SG_ 1552 EKS_DiagRespData1 "Data1";
CM_ SG_ 1552 EKS_DiagRespData2 "Data2";
CM_ SG_ 1552 EKS_DiagRespData3 "Data3";
CM_ SG_ 1552 EKS_DiagRespData4 "Data4";
CM_ SG_ 1552 EKS_DiagRespData5 "Data5";
CM_ SG_ 1552 EKS_DiagRespData6 "Data6";
CM_ SG_ 1552 EKS_DiagRespData7 "Data7";
CM_ SG_ 1683 BMS_DiagReqData0 "Data0";
CM_ SG_ 1683 BMS_DiagReqData1 "Data1";
CM_ SG_ 1683 BMS_DiagReqData2 "Data2";
CM_ SG_ 1683 BMS_DiagReqData3 "Data3";
CM_ SG_ 1683 BMS_DiagReqData4 "Data4";
CM_ SG_ 1683 BMS_DiagReqData5 "Data5";
CM_ SG_ 1683 BMS_DiagReqData6 "Data6";
CM_ SG_ 1683 BMS_DiagReqData7 "Data7";
CM_ SG_ 1555 BMS_DiagRespData0 "Data0";
CM_ SG_ 1555 BMS_DiagRespData1 "Data1";
CM_ SG_ 1555 BMS_DiagRespData2 "Data2";
CM_ SG_ 1555 BMS_DiagRespData3 "Data3";
CM_ SG_ 1555 BMS_DiagRespData4 "Data4";
CM_ SG_ 1555 BMS_DiagRespData5 "Data5";
CM_ SG_ 1555 BMS_DiagRespData6 "Data6";
CM_ SG_ 1555 BMS_DiagRespData7 "Data7";
CM_ SG_ 1708 VCU_DiagReqData0 "Data0";
CM_ SG_ 1708 VCU_DiagReqData1 "Data1";
CM_ SG_ 1708 VCU_DiagReqData2 "Data2";
CM_ SG_ 1708 VCU_DiagReqData3 "Data3";
CM_ SG_ 1708 VCU_DiagReqData4 "Data4";
CM_ SG_ 1708 VCU_DiagReqData5 "Data5";
CM_ SG_ 1708 VCU_DiagReqData6 "Data6";
CM_ SG_ 1708 VCU_DiagReqData7 "Data7";
CM_ SG_ 1580 VCU_DiagRespData0 "Data0";
CM_ SG_ 1580 VCU_DiagRespData1 "Data1";
CM_ SG_ 1580 VCU_DiagRespData2 "Data2";
CM_ SG_ 1580 VCU_DiagRespData3 "Data3";
CM_ SG_ 1580 VCU_DiagRespData4 "Data4";
CM_ SG_ 1580 VCU_DiagRespData5 "Data5";
CM_ SG_ 1580 VCU_DiagRespData6 "Data6";
CM_ SG_ 1580 VCU_DiagRespData7 "Data7";
CM_ SG_ 1725 PDU_DiagReqData0 "Data0";
CM_ SG_ 1725 PDU_DiagReqData1 "Data1";
CM_ SG_ 1725 PDU_DiagReqData2 "Data2";
CM_ SG_ 1725 PDU_DiagReqData3 "Data3";
CM_ SG_ 1725 PDU_DiagReqData4 "Data4";
CM_ SG_ 1725 PDU_DiagReqData5 "Data5";
CM_ SG_ 1725 PDU_DiagReqData6 "Data6";
CM_ SG_ 1725 PDU_DiagReqData7 "Data7";
CM_ SG_ 1597 PDU_DiagRespData0 "Data0";
CM_ SG_ 1597 PDU_DiagRespData1 "Data1";
CM_ SG_ 1597 PDU_DiagRespData2 "Data2";
CM_ SG_ 1597 PDU_DiagRespData3 "Data3";
CM_ SG_ 1597 PDU_DiagRespData4 "Data4";
CM_ SG_ 1597 PDU_DiagRespData5 "Data5";
CM_ SG_ 1597 PDU_DiagRespData6 "Data6";
CM_ SG_ 1597 PDU_DiagRespData7 "Data7";
CM_ SG_ 1691 EDS_DiagReqData0 "Data0";
CM_ SG_ 1691 EDS_DiagReqData1 "Data1";
CM_ SG_ 1691 EDS_DiagReqData2 "Data2";
CM_ SG_ 1691 EDS_DiagReqData3 "Data3";
CM_ SG_ 1691 EDS_DiagReqData4 "Data4";
CM_ SG_ 1691 EDS_DiagReqData5 "Data5";
CM_ SG_ 1691 EDS_DiagReqData6 "Data6";
CM_ SG_ 1691 EDS_DiagReqData7 "Data7";
CM_ SG_ 1563 EDS_DiagRespData0 "Data0";
CM_ SG_ 1563 EDS_DiagRespData1 "Data1";
CM_ SG_ 1563 EDS_DiagRespData2 "Data2";
CM_ SG_ 1563 EDS_DiagRespData3 "Data3";
CM_ SG_ 1563 EDS_DiagRespData4 "Data4";
CM_ SG_ 1563 EDS_DiagRespData5 "Data5";
CM_ SG_ 1563 EDS_DiagRespData6 "Data6";
CM_ SG_ 1563 EDS_DiagRespData7 "Data7";
CM_ SG_ 1781 EAC_DiagReqData0 "Data0";
CM_ SG_ 1781 EAC_DiagReqData1 "Data1";
CM_ SG_ 1781 EAC_DiagReqData2 "Data2";
CM_ SG_ 1781 EAC_DiagReqData3 "Data3";
CM_ SG_ 1781 EAC_DiagReqData4 "Data4";
CM_ SG_ 1781 EAC_DiagReqData5 "Data5";
CM_ SG_ 1781 EAC_DiagReqData6 "Data6";
CM_ SG_ 1781 EAC_DiagReqData7 "Data7";
CM_ SG_ 1653 EAC_DiagRespData0 "Data0";
CM_ SG_ 1653 EAC_DiagRespData1 "Data1";
CM_ SG_ 1653 EAC_DiagRespData2 "Data2";
CM_ SG_ 1653 EAC_DiagRespData3 "Data3";
CM_ SG_ 1653 EAC_DiagRespData4 "Data4";
CM_ SG_ 1653 EAC_DiagRespData5 "Data5";
CM_ SG_ 1653 EAC_DiagRespData6 "Data6";
CM_ SG_ 1653 EAC_DiagRespData7 "Data7";
CM_ SG_ 1695 EVCC_DiagReqData0 "Data0";
CM_ SG_ 1695 EVCC_DiagReqData1 "Data1";
CM_ SG_ 1695 EVCC_DiagReqData2 "Data2";
CM_ SG_ 1695 EVCC_DiagReqData3 "Data3";
CM_ SG_ 1695 EVCC_DiagReqData4 "Data4";
CM_ SG_ 1695 EVCC_DiagReqData5 "Data5";
CM_ SG_ 1695 EVCC_DiagReqData6 "Data6";
CM_ SG_ 1695 EVCC_DiagReqData7 "Data7";
CM_ SG_ 1567 EVCC_DiagRespData0 "Data0";
CM_ SG_ 1567 EVCC_DiagRespData1 "Data1";
CM_ SG_ 1567 EVCC_DiagRespData2 "Data2";
CM_ SG_ 1567 EVCC_DiagRespData3 "Data3";
CM_ SG_ 1567 EVCC_DiagRespData4 "Data4";
CM_ SG_ 1567 EVCC_DiagRespData5 "Data5";
CM_ SG_ 1567 EVCC_DiagRespData6 "Data6";
CM_ SG_ 1567 EVCC_DiagRespData7 "Data7";
CM_ SG_ 1668 MHU_DiagReqData0 "Data0";
CM_ SG_ 1668 MHU_DiagReqData1 "Data1";
CM_ SG_ 1668 MHU_DiagReqData2 "Data2";
CM_ SG_ 1668 MHU_DiagReqData3 "Data3";
CM_ SG_ 1668 MHU_DiagReqData4 "Data4";
CM_ SG_ 1668 MHU_DiagReqData5 "Data5";
CM_ SG_ 1668 MHU_DiagReqData6 "Data6";
CM_ SG_ 1668 MHU_DiagReqData7 "Data7";
CM_ SG_ 1540 MHU_DiagRespData0 "Data0";
CM_ SG_ 1540 MHU_DiagRespData1 "Data1";
CM_ SG_ 1540 MHU_DiagRespData2 "Data2";
CM_ SG_ 1540 MHU_DiagRespData3 "Data3";
CM_ SG_ 1540 MHU_DiagRespData4 "Data4";
CM_ SG_ 1540 MHU_DiagRespData5 "Data5";
CM_ SG_ 1540 MHU_DiagRespData6 "Data6";
CM_ SG_ 1540 MHU_DiagRespData7 "Data7";
CM_ SG_ 1667 IPC_DiagReqData0 "Data0";
CM_ SG_ 1667 IPC_DiagReqData1 "Data1";
CM_ SG_ 1667 IPC_DiagReqData2 "Data2";
CM_ SG_ 1667 IPC_DiagReqData3 "Data3";
CM_ SG_ 1667 IPC_DiagReqData4 "Data4";
CM_ SG_ 1667 IPC_DiagReqData5 "Data5";
CM_ SG_ 1667 IPC_DiagReqData6 "Data6";
CM_ SG_ 1667 IPC_DiagReqData7 "Data7";
CM_ SG_ 1539 IPC_DiagRespData0 "Data0";
CM_ SG_ 1539 IPC_DiagRespData1 "Data1";
CM_ SG_ 1539 IPC_DiagRespData2 "Data2";
CM_ SG_ 1539 IPC_DiagRespData3 "Data3";
CM_ SG_ 1539 IPC_DiagRespData4 "Data4";
CM_ SG_ 1539 IPC_DiagRespData5 "Data5";
CM_ SG_ 1539 IPC_DiagRespData6 "Data6";
CM_ SG_ 1539 IPC_DiagRespData7 "Data7";
CM_ SG_ 1673 CCU_DiagReqData0 "Data0";
CM_ SG_ 1673 CCU_DiagReqData1 "Data1";
CM_ SG_ 1673 CCU_DiagReqData2 "Data2";
CM_ SG_ 1673 CCU_DiagReqData3 "Data3";
CM_ SG_ 1673 CCU_DiagReqData4 "Data4";
CM_ SG_ 1673 CCU_DiagReqData5 "Data5";
CM_ SG_ 1673 CCU_DiagReqData6 "Data6";
CM_ SG_ 1673 CCU_DiagReqData7 "Data7";
CM_ SG_ 1545 CCU_DiagRespData0 "Data0";
CM_ SG_ 1545 CCU_DiagRespData1 "Data1";
CM_ SG_ 1545 CCU_DiagRespData2 "Data2";
CM_ SG_ 1545 CCU_DiagRespData3 "Data3";
CM_ SG_ 1545 CCU_DiagRespData4 "Data4";
CM_ SG_ 1545 CCU_DiagRespData5 "Data5";
CM_ SG_ 1545 CCU_DiagRespData6 "Data6";
CM_ SG_ 1545 CCU_DiagRespData7 "Data7";
CM_ SG_ 1666 XGW_DiagReqData0 "Data0";
CM_ SG_ 1666 XGW_DiagReqData1 "Data1";
CM_ SG_ 1666 XGW_DiagReqData2 "Data2";
CM_ SG_ 1666 XGW_DiagReqData3 "Data3";
CM_ SG_ 1666 XGW_DiagReqData4 "Data4";
CM_ SG_ 1666 XGW_DiagReqData5 "Data5";
CM_ SG_ 1666 XGW_DiagReqData6 "Data6";
CM_ SG_ 1666 XGW_DiagReqData7 "Data7";
CM_ SG_ 1538 XGW_DiagRespData0 "Data0";
CM_ SG_ 1538 XGW_DiagRespData1 "Data1";
CM_ SG_ 1538 XGW_DiagRespData2 "Data2";
CM_ SG_ 1538 XGW_DiagRespData3 "Data3";
CM_ SG_ 1538 XGW_DiagRespData4 "Data4";
CM_ SG_ 1538 XGW_DiagRespData5 "Data5";
CM_ SG_ 1538 XGW_DiagRespData6 "Data6";
CM_ SG_ 1538 XGW_DiagRespData7 "Data7";
CM_ SG_ 1706 AVAS_DiagReqData0 "Data0";
CM_ SG_ 1706 AVAS_DiagReqData1 "Data1";
CM_ SG_ 1706 AVAS_DiagReqData2 "Data2";
CM_ SG_ 1706 AVAS_DiagReqData3 "Data3";
CM_ SG_ 1706 AVAS_DiagReqData4 "Data4";
CM_ SG_ 1706 AVAS_DiagReqData5 "Data5";
CM_ SG_ 1706 AVAS_DiagReqData6 "Data6";
CM_ SG_ 1706 AVAS_DiagReqData7 "Data7";
CM_ SG_ 1578 AVAS_DiagRespData0 "Data0";
CM_ SG_ 1578 AVAS_DiagRespData1 "Data1";
CM_ SG_ 1578 AVAS_DiagRespData2 "Data2";
CM_ SG_ 1578 AVAS_DiagRespData3 "Data3";
CM_ SG_ 1578 AVAS_DiagRespData4 "Data4";
CM_ SG_ 1578 AVAS_DiagRespData5 "Data5";
CM_ SG_ 1578 AVAS_DiagRespData6 "Data6";
CM_ SG_ 1578 AVAS_DiagRespData7 "Data7";
CM_ SG_ 1791 GW_DiagFunctionalAddressingData0 "Data0";
CM_ SG_ 1791 GW_DiagFunctionalAddressingData1 "Data1";
CM_ SG_ 1791 GW_DiagFunctionalAddressingData2 "Data2";
CM_ SG_ 1791 GW_DiagFunctionalAddressingData3 "Data3";
CM_ SG_ 1791 GW_DiagFunctionalAddressingData4 "Data4";
CM_ SG_ 1791 GW_DiagFunctionalAddressingData5 "Data5";
CM_ SG_ 1791 GW_DiagFunctionalAddressingData6 "Data6";
CM_ SG_ 1791 GW_DiagFunctionalAddressingData7 "Data7";
BA_DEF_ BO_ "DiagRequest" ENUM "No","Yes";
BA_DEF_ BO_ "DiagResponse" ENUM "No","Yes";
BA_DEF_ BO_ "DiagState" ENUM "No","Yes";
BA_DEF_ BO_ "GenMsgCycleTime" INT 0 65535;
BA_DEF_ BO_ "GenMsgCycleTimeFast" INT 0 65535;
BA_DEF_ BO_ "GenMsgDelayTime" INT 0 65535;
BA_DEF_ BO_ "GenMsgILSupport" ENUM "No","Yes";
BA_DEF_ BO_ "GenMsgNrOfRepetition" INT 0 65535;
BA_DEF_ BO_ "GenMsgSendType" ENUM  "Cycle","Event","IfActive","CE","CA";
BA_DEF_ SG_ "GenSigSendType" ENUM  "Cycle","OnWrite","OnWriteWithRepetition","OnChange","OnChangeWithRepetition","IfActive","IfActiveWithRepetition";
BA_DEF_ SG_ "GenSigStartValue" INT 0 2147483647;
BA_DEF_ SG_ "GenSigInvalidValue" INT 0 2147483647;
BA_DEF_ SG_ "GenSigInactiveValue" INT 0 2147483647;
BA_DEF_ BU_ "ILUsed" ENUM  "No","Yes";
BA_DEF_ BU_ "NmAsrCanMsgReducedTime" INT 320 640;
BA_DEF_  "Baudrate" INT 0 1000000;
BA_DEF_  "BusType" STRING;
BA_DEF_  "Manufacturer" STRING;
BA_DEF_  "NmAsrBaseAddress" HEX 0 2047;
BA_DEF_  "NmAsrCanMsgCycleTime" INT 0 65535;
BA_DEF_  "NmAsrMessageCount" INT 1 256;
BA_DEF_  "NmAsrRepeatMessageTime" INT 0 65535;
BA_DEF_  "NmAsrTimeoutTime" INT 0 65535;
BA_DEF_  "NmAsrWaitBusSleepTime" INT 0 65535;
BA_DEF_  "NmType" STRING;
BA_DEF_DEF_ "Baudrate" 500000;
BA_DEF_DEF_ "BusType" "CAN";
BA_DEF_DEF_ "DiagRequest" "No";
BA_DEF_DEF_ "DiagResponse" "No";
BA_DEF_DEF_ "DiagState" "No";
BA_DEF_DEF_ "GenMsgCycleTime" 0;
BA_DEF_DEF_ "GenMsgCycleTimeFast" 0;
BA_DEF_DEF_ "GenMsgDelayTime" 0;
BA_DEF_DEF_ "GenMsgILSupport" "Yes";
BA_DEF_DEF_ "GenMsgNrOfRepetition" 0;
BA_DEF_DEF_ "GenMsgSendType" "NoMsgSendType";
BA_DEF_DEF_ "GenSigSendType" "NoSigSendType";
BA_DEF_DEF_ "GenSigStartValue" 0;
BA_DEF_DEF_  "GenSigInvalidValue" 0;
BA_DEF_DEF_ "GenSigInactiveValue" 0;
BA_DEF_DEF_ "ILUsed" "Yes";
BA_DEF_DEF_ "Manufacturer" "Launch";
BA_DEF_DEF_ "NmAsrBaseAddress" 1280;
BA_DEF_DEF_ "NmAsrCanMsgCycleTime" 640;
BA_DEF_DEF_ "NmAsrCanMsgReducedTime" 320;
BA_DEF_DEF_ "NmAsrMessageCount" 128;
BA_DEF_DEF_ "NmAsrRepeatMessageTime" 3200;
BA_DEF_DEF_ "NmAsrTimeoutTime" 2000;
BA_DEF_DEF_ "NmAsrWaitBusSleepTime" 1500;
BA_DEF_DEF_ "NmType" "NmAsr";

BA_ "GenMsgSendType" BO_ 1672 1;
BA_ "DiagRequest" BO_ 1672 1;
BA_ "GenMsgSendType" BO_ 1544 1;
BA_ "DiagResponse" BO_ 1544 1;
BA_ "GenMsgSendType" BO_ 1665 1;
BA_ "DiagRequest" BO_ 1665 1;
BA_ "GenMsgSendType" BO_ 1537 1;
BA_ "DiagResponse" BO_ 1537 1;
BA_ "GenMsgSendType" BO_ 1728 1;
BA_ "DiagRequest" BO_ 1728 1;
BA_ "GenMsgSendType" BO_ 1600 1;
BA_ "DiagResponse" BO_ 1600 1;
BA_ "GenMsgSendType" BO_ 1705 1;
BA_ "DiagRequest" BO_ 1705 1;
BA_ "GenMsgSendType" BO_ 1577 1;
BA_ "DiagResponse" BO_ 1577 1;
BA_ "GenMsgSendType" BO_ 1704 1;
BA_ "DiagRequest" BO_ 1704 1;
BA_ "GenMsgSendType" BO_ 1576 1;
BA_ "DiagResponse" BO_ 1576 1;
BA_ "GenMsgSendType" BO_ 1680 1;
BA_ "DiagRequest" BO_ 1680 1;
BA_ "GenMsgSendType" BO_ 1552 1;
BA_ "DiagResponse" BO_ 1552 1;
BA_ "GenMsgSendType" BO_ 1683 1;
BA_ "DiagRequest" BO_ 1683 1;
BA_ "GenMsgSendType" BO_ 1555 1;
BA_ "DiagResponse" BO_ 1555 1;
BA_ "GenMsgSendType" BO_ 1708 1;
BA_ "DiagRequest" BO_ 1708 1;
BA_ "GenMsgSendType" BO_ 1580 1;
BA_ "DiagResponse" BO_ 1580 1;
BA_ "GenMsgSendType" BO_ 1725 1;
BA_ "DiagRequest" BO_ 1725 1;
BA_ "GenMsgSendType" BO_ 1597 1;
BA_ "DiagResponse" BO_ 1597 1;
BA_ "GenMsgSendType" BO_ 1691 1;
BA_ "DiagRequest" BO_ 1691 1;
BA_ "GenMsgSendType" BO_ 1563 1;
BA_ "DiagResponse" BO_ 1563 1;
BA_ "GenMsgSendType" BO_ 1781 1;
BA_ "DiagRequest" BO_ 1781 1;
BA_ "GenMsgSendType" BO_ 1653 1;
BA_ "DiagResponse" BO_ 1653 1;
BA_ "GenMsgSendType" BO_ 1695 1;
BA_ "DiagRequest" BO_ 1695 1;
BA_ "GenMsgSendType" BO_ 1567 1;
BA_ "DiagResponse" BO_ 1567 1;
BA_ "GenMsgSendType" BO_ 1668 1;
BA_ "DiagRequest" BO_ 1668 1;
BA_ "GenMsgSendType" BO_ 1540 1;
BA_ "DiagResponse" BO_ 1540 1;
BA_ "GenMsgSendType" BO_ 1667 1;
BA_ "DiagRequest" BO_ 1667 1;
BA_ "GenMsgSendType" BO_ 1539 1;
BA_ "DiagResponse" BO_ 1539 1;
BA_ "GenMsgSendType" BO_ 1673 1;
BA_ "DiagRequest" BO_ 1673 1;
BA_ "GenMsgSendType" BO_ 1545 1;
BA_ "DiagResponse" BO_ 1545 1;
BA_ "GenMsgSendType" BO_ 1666 1;
BA_ "DiagRequest" BO_ 1666 1;
BA_ "GenMsgSendType" BO_ 1538 1;
BA_ "DiagResponse" BO_ 1538 1;
BA_ "GenMsgSendType" BO_ 1706 1;
BA_ "DiagRequest" BO_ 1706 1;
BA_ "GenMsgSendType" BO_ 1578 1;
BA_ "DiagResponse" BO_ 1578 1;
BA_ "GenMsgSendType" BO_ 1791 1;
BA_ "DiagState" BO_ 1791 1;
BA_ "GenSigSendType" SG_ 1672 ACM_DiagReqData0 0;
BA_ "GenSigSendType" SG_ 1672 ACM_DiagReqData1 0;
BA_ "GenSigSendType" SG_ 1672 ACM_DiagReqData2 0;
BA_ "GenSigSendType" SG_ 1672 ACM_DiagReqData3 0;
BA_ "GenSigSendType" SG_ 1672 ACM_DiagReqData4 0;
BA_ "GenSigSendType" SG_ 1672 ACM_DiagReqData5 0;
BA_ "GenSigSendType" SG_ 1672 ACM_DiagReqData6 0;
BA_ "GenSigSendType" SG_ 1672 ACM_DiagReqData7 0;
BA_ "GenSigSendType" SG_ 1544 ACM_DiagRespData0 0;
BA_ "GenSigSendType" SG_ 1544 ACM_DiagRespData1 0;
BA_ "GenSigSendType" SG_ 1544 ACM_DiagRespData2 0;
BA_ "GenSigSendType" SG_ 1544 ACM_DiagRespData3 0;
BA_ "GenSigSendType" SG_ 1544 ACM_DiagRespData4 0;
BA_ "GenSigSendType" SG_ 1544 ACM_DiagRespData5 0;
BA_ "GenSigSendType" SG_ 1544 ACM_DiagRespData6 0;
BA_ "GenSigSendType" SG_ 1544 ACM_DiagRespData7 0;
BA_ "GenSigSendType" SG_ 1665 BCM_DiagReq_Data0 0;
BA_ "GenSigSendType" SG_ 1665 BCM_DiagReq_Data1 0;
BA_ "GenSigSendType" SG_ 1665 BCM_DiagReq_Data2 0;
BA_ "GenSigSendType" SG_ 1665 BCM_DiagReq_Data3 0;
BA_ "GenSigSendType" SG_ 1665 BCM_DiagReq_Data4 0;
BA_ "GenSigSendType" SG_ 1665 BCM_DiagReq_Data5 0;
BA_ "GenSigSendType" SG_ 1665 BCM_DiagReq_Data6 0;
BA_ "GenSigSendType" SG_ 1665 BCM_DiagReq_Data7 0;
BA_ "GenSigSendType" SG_ 1537 BCM_DiagResp_Data0 0;
BA_ "GenSigSendType" SG_ 1537 BCM_DiagResp_Data1 0;
BA_ "GenSigSendType" SG_ 1537 BCM_DiagResp_Data2 0;
BA_ "GenSigSendType" SG_ 1537 BCM_DiagResp_Data3 0;
BA_ "GenSigSendType" SG_ 1537 BCM_DiagResp_Data4 0;
BA_ "GenSigSendType" SG_ 1537 BCM_DiagResp_Data5 0;
BA_ "GenSigSendType" SG_ 1537 BCM_DiagResp_Data6 0;
BA_ "GenSigSendType" SG_ 1537 BCM_DiagResp_Data7 0;
BA_ "GenSigSendType" SG_ 1728 BSD_DiagReq_Data0 0;
BA_ "GenSigSendType" SG_ 1728 BSD_DiagReq_Data1 0;
BA_ "GenSigSendType" SG_ 1728 BSD_DiagReq_Data2 0;
BA_ "GenSigSendType" SG_ 1728 BSD_DiagReq_Data3 0;
BA_ "GenSigSendType" SG_ 1728 BSD_DiagReq_Data4 0;
BA_ "GenSigSendType" SG_ 1728 BSD_DiagReq_Data5 0;
BA_ "GenSigSendType" SG_ 1728 BSD_DiagReq_Data6 0;
BA_ "GenSigSendType" SG_ 1728 BSD_DiagReq_Data7 0;
BA_ "GenSigSendType" SG_ 1600 BSD_DiagResp_Data0 0;
BA_ "GenSigSendType" SG_ 1600 BSD_DiagResp_Data1 0;
BA_ "GenSigSendType" SG_ 1600 BSD_DiagResp_Data2 0;
BA_ "GenSigSendType" SG_ 1600 BSD_DiagResp_Data3 0;
BA_ "GenSigSendType" SG_ 1600 BSD_DiagResp_Data4 0;
BA_ "GenSigSendType" SG_ 1600 BSD_DiagResp_Data5 0;
BA_ "GenSigSendType" SG_ 1600 BSD_DiagResp_Data6 0;
BA_ "GenSigSendType" SG_ 1600 BSD_DiagResp_Data7 0;
BA_ "GenSigSendType" SG_ 1705 ESC_DiagReqData0 0;
BA_ "GenSigSendType" SG_ 1705 ESC_DiagReqData1 0;
BA_ "GenSigSendType" SG_ 1705 ESC_DiagReqData2 0;
BA_ "GenSigSendType" SG_ 1705 ESC_DiagReqData3 0;
BA_ "GenSigSendType" SG_ 1705 ESC_DiagReqData4 0;
BA_ "GenSigSendType" SG_ 1705 ESC_DiagReqData5 0;
BA_ "GenSigSendType" SG_ 1705 ESC_DiagReqData6 0;
BA_ "GenSigSendType" SG_ 1705 ESC_DiagReqData7 0;
BA_ "GenSigSendType" SG_ 1577 ESC_DiagRespData0 0;
BA_ "GenSigSendType" SG_ 1577 ESC_DiagRespData1 0;
BA_ "GenSigSendType" SG_ 1577 ESC_DiagRespData2 0;
BA_ "GenSigSendType" SG_ 1577 ESC_DiagRespData3 0;
BA_ "GenSigSendType" SG_ 1577 ESC_DiagRespData4 0;
BA_ "GenSigSendType" SG_ 1577 ESC_DiagRespData5 0;
BA_ "GenSigSendType" SG_ 1577 ESC_DiagRespData6 0;
BA_ "GenSigSendType" SG_ 1577 ESC_DiagRespData7 0;
BA_ "GenSigSendType" SG_ 1704 EPS_DiagReqData0 0;
BA_ "GenSigSendType" SG_ 1704 EPS_DiagReqData1 0;
BA_ "GenSigSendType" SG_ 1704 EPS_DiagReqData2 0;
BA_ "GenSigSendType" SG_ 1704 EPS_DiagReqData3 0;
BA_ "GenSigSendType" SG_ 1704 EPS_DiagReqData4 0;
BA_ "GenSigSendType" SG_ 1704 EPS_DiagReqData5 0;
BA_ "GenSigSendType" SG_ 1704 EPS_DiagReqData6 0;
BA_ "GenSigSendType" SG_ 1704 EPS_DiagReqData7 0;
BA_ "GenSigSendType" SG_ 1576 EPS_DiagRespData0 0;
BA_ "GenSigSendType" SG_ 1576 EPS_DiagRespData1 0;
BA_ "GenSigSendType" SG_ 1576 EPS_DiagRespData2 0;
BA_ "GenSigSendType" SG_ 1576 EPS_DiagRespData3 0;
BA_ "GenSigSendType" SG_ 1576 EPS_DiagRespData4 0;
BA_ "GenSigSendType" SG_ 1576 EPS_DiagRespData5 0;
BA_ "GenSigSendType" SG_ 1576 EPS_DiagRespData6 0;
BA_ "GenSigSendType" SG_ 1576 EPS_DiagRespData7 0;
BA_ "GenSigSendType" SG_ 1680 EKS_DiagReqData0 0;
BA_ "GenSigSendType" SG_ 1680 EKS_DiagReqData1 0;
BA_ "GenSigSendType" SG_ 1680 EKS_DiagReqData2 0;
BA_ "GenSigSendType" SG_ 1680 EKS_DiagReqData3 0;
BA_ "GenSigSendType" SG_ 1680 EKS_DiagReqData4 0;
BA_ "GenSigSendType" SG_ 1680 EKS_DiagReqData5 0;
BA_ "GenSigSendType" SG_ 1680 EKS_DiagReqData6 0;
BA_ "GenSigSendType" SG_ 1680 EKS_DiagReqData7 0;
BA_ "GenSigSendType" SG_ 1552 EKS_DiagRespData0 0;
BA_ "GenSigSendType" SG_ 1552 EKS_DiagRespData1 0;
BA_ "GenSigSendType" SG_ 1552 EKS_DiagRespData2 0;
BA_ "GenSigSendType" SG_ 1552 EKS_DiagRespData3 0;
BA_ "GenSigSendType" SG_ 1552 EKS_DiagRespData4 0;
BA_ "GenSigSendType" SG_ 1552 EKS_DiagRespData5 0;
BA_ "GenSigSendType" SG_ 1552 EKS_DiagRespData6 0;
BA_ "GenSigSendType" SG_ 1552 EKS_DiagRespData7 0;
BA_ "GenSigSendType" SG_ 1683 BMS_DiagReqData0 0;
BA_ "GenSigSendType" SG_ 1683 BMS_DiagReqData1 0;
BA_ "GenSigSendType" SG_ 1683 BMS_DiagReqData2 0;
BA_ "GenSigSendType" SG_ 1683 BMS_DiagReqData3 0;
BA_ "GenSigSendType" SG_ 1683 BMS_DiagReqData4 0;
BA_ "GenSigSendType" SG_ 1683 BMS_DiagReqData5 0;
BA_ "GenSigSendType" SG_ 1683 BMS_DiagReqData6 0;
BA_ "GenSigSendType" SG_ 1683 BMS_DiagReqData7 0;
BA_ "GenSigSendType" SG_ 1555 BMS_DiagRespData0 0;
BA_ "GenSigSendType" SG_ 1555 BMS_DiagRespData1 0;
BA_ "GenSigSendType" SG_ 1555 BMS_DiagRespData2 0;
BA_ "GenSigSendType" SG_ 1555 BMS_DiagRespData3 0;
BA_ "GenSigSendType" SG_ 1555 BMS_DiagRespData4 0;
BA_ "GenSigSendType" SG_ 1555 BMS_DiagRespData5 0;
BA_ "GenSigSendType" SG_ 1555 BMS_DiagRespData6 0;
BA_ "GenSigSendType" SG_ 1555 BMS_DiagRespData7 0;
BA_ "GenSigSendType" SG_ 1708 VCU_DiagReqData0 0;
BA_ "GenSigSendType" SG_ 1708 VCU_DiagReqData1 0;
BA_ "GenSigSendType" SG_ 1708 VCU_DiagReqData2 0;
BA_ "GenSigSendType" SG_ 1708 VCU_DiagReqData3 0;
BA_ "GenSigSendType" SG_ 1708 VCU_DiagReqData4 0;
BA_ "GenSigSendType" SG_ 1708 VCU_DiagReqData5 0;
BA_ "GenSigSendType" SG_ 1708 VCU_DiagReqData6 0;
BA_ "GenSigSendType" SG_ 1708 VCU_DiagReqData7 0;
BA_ "GenSigSendType" SG_ 1580 VCU_DiagRespData0 0;
BA_ "GenSigSendType" SG_ 1580 VCU_DiagRespData1 0;
BA_ "GenSigSendType" SG_ 1580 VCU_DiagRespData2 0;
BA_ "GenSigSendType" SG_ 1580 VCU_DiagRespData3 0;
BA_ "GenSigSendType" SG_ 1580 VCU_DiagRespData4 0;
BA_ "GenSigSendType" SG_ 1580 VCU_DiagRespData5 0;
BA_ "GenSigSendType" SG_ 1580 VCU_DiagRespData6 0;
BA_ "GenSigSendType" SG_ 1580 VCU_DiagRespData7 0;
BA_ "GenSigSendType" SG_ 1725 PDU_DiagReqData0 0;
BA_ "GenSigSendType" SG_ 1725 PDU_DiagReqData1 0;
BA_ "GenSigSendType" SG_ 1725 PDU_DiagReqData2 0;
BA_ "GenSigSendType" SG_ 1725 PDU_DiagReqData3 0;
BA_ "GenSigSendType" SG_ 1725 PDU_DiagReqData4 0;
BA_ "GenSigSendType" SG_ 1725 PDU_DiagReqData5 0;
BA_ "GenSigSendType" SG_ 1725 PDU_DiagReqData6 0;
BA_ "GenSigSendType" SG_ 1725 PDU_DiagReqData7 0;
BA_ "GenSigSendType" SG_ 1597 PDU_DiagRespData0 0;
BA_ "GenSigSendType" SG_ 1597 PDU_DiagRespData1 0;
BA_ "GenSigSendType" SG_ 1597 PDU_DiagRespData2 0;
BA_ "GenSigSendType" SG_ 1597 PDU_DiagRespData3 0;
BA_ "GenSigSendType" SG_ 1597 PDU_DiagRespData4 0;
BA_ "GenSigSendType" SG_ 1597 PDU_DiagRespData5 0;
BA_ "GenSigSendType" SG_ 1597 PDU_DiagRespData6 0;
BA_ "GenSigSendType" SG_ 1597 PDU_DiagRespData7 0;
BA_ "GenSigSendType" SG_ 1691 EDS_DiagReqData0 0;
BA_ "GenSigSendType" SG_ 1691 EDS_DiagReqData1 0;
BA_ "GenSigSendType" SG_ 1691 EDS_DiagReqData2 0;
BA_ "GenSigSendType" SG_ 1691 EDS_DiagReqData3 0;
BA_ "GenSigSendType" SG_ 1691 EDS_DiagReqData4 0;
BA_ "GenSigSendType" SG_ 1691 EDS_DiagReqData5 0;
BA_ "GenSigSendType" SG_ 1691 EDS_DiagReqData6 0;
BA_ "GenSigSendType" SG_ 1691 EDS_DiagReqData7 0;
BA_ "GenSigSendType" SG_ 1563 EDS_DiagRespData0 0;
BA_ "GenSigSendType" SG_ 1563 EDS_DiagRespData1 0;
BA_ "GenSigSendType" SG_ 1563 EDS_DiagRespData2 0;
BA_ "GenSigSendType" SG_ 1563 EDS_DiagRespData3 0;
BA_ "GenSigSendType" SG_ 1563 EDS_DiagRespData4 0;
BA_ "GenSigSendType" SG_ 1563 EDS_DiagRespData5 0;
BA_ "GenSigSendType" SG_ 1563 EDS_DiagRespData6 0;
BA_ "GenSigSendType" SG_ 1563 EDS_DiagRespData7 0;
BA_ "GenSigSendType" SG_ 1781 EAC_DiagReqData0 0;
BA_ "GenSigSendType" SG_ 1781 EAC_DiagReqData1 0;
BA_ "GenSigSendType" SG_ 1781 EAC_DiagReqData2 0;
BA_ "GenSigSendType" SG_ 1781 EAC_DiagReqData3 0;
BA_ "GenSigSendType" SG_ 1781 EAC_DiagReqData4 0;
BA_ "GenSigSendType" SG_ 1781 EAC_DiagReqData5 0;
BA_ "GenSigSendType" SG_ 1781 EAC_DiagReqData6 0;
BA_ "GenSigSendType" SG_ 1781 EAC_DiagReqData7 0;
BA_ "GenSigSendType" SG_ 1653 EAC_DiagRespData0 0;
BA_ "GenSigSendType" SG_ 1653 EAC_DiagRespData1 0;
BA_ "GenSigSendType" SG_ 1653 EAC_DiagRespData2 0;
BA_ "GenSigSendType" SG_ 1653 EAC_DiagRespData3 0;
BA_ "GenSigSendType" SG_ 1653 EAC_DiagRespData4 0;
BA_ "GenSigSendType" SG_ 1653 EAC_DiagRespData5 0;
BA_ "GenSigSendType" SG_ 1653 EAC_DiagRespData6 0;
BA_ "GenSigSendType" SG_ 1653 EAC_DiagRespData7 0;
BA_ "GenSigSendType" SG_ 1695 EVCC_DiagReqData0 0;
BA_ "GenSigSendType" SG_ 1695 EVCC_DiagReqData1 0;
BA_ "GenSigSendType" SG_ 1695 EVCC_DiagReqData2 0;
BA_ "GenSigSendType" SG_ 1695 EVCC_DiagReqData3 0;
BA_ "GenSigSendType" SG_ 1695 EVCC_DiagReqData4 0;
BA_ "GenSigSendType" SG_ 1695 EVCC_DiagReqData5 0;
BA_ "GenSigSendType" SG_ 1695 EVCC_DiagReqData6 0;
BA_ "GenSigSendType" SG_ 1695 EVCC_DiagReqData7 0;
BA_ "GenSigSendType" SG_ 1567 EVCC_DiagRespData0 0;
BA_ "GenSigSendType" SG_ 1567 EVCC_DiagRespData1 0;
BA_ "GenSigSendType" SG_ 1567 EVCC_DiagRespData2 0;
BA_ "GenSigSendType" SG_ 1567 EVCC_DiagRespData3 0;
BA_ "GenSigSendType" SG_ 1567 EVCC_DiagRespData4 0;
BA_ "GenSigSendType" SG_ 1567 EVCC_DiagRespData5 0;
BA_ "GenSigSendType" SG_ 1567 EVCC_DiagRespData6 0;
BA_ "GenSigSendType" SG_ 1567 EVCC_DiagRespData7 0;
BA_ "GenSigSendType" SG_ 1668 MHU_DiagReqData0 0;
BA_ "GenSigSendType" SG_ 1668 MHU_DiagReqData1 0;
BA_ "GenSigSendType" SG_ 1668 MHU_DiagReqData2 0;
BA_ "GenSigSendType" SG_ 1668 MHU_DiagReqData3 0;
BA_ "GenSigSendType" SG_ 1668 MHU_DiagReqData4 0;
BA_ "GenSigSendType" SG_ 1668 MHU_DiagReqData5 0;
BA_ "GenSigSendType" SG_ 1668 MHU_DiagReqData6 0;
BA_ "GenSigSendType" SG_ 1668 MHU_DiagReqData7 0;
BA_ "GenSigSendType" SG_ 1540 MHU_DiagRespData0 0;
BA_ "GenSigSendType" SG_ 1540 MHU_DiagRespData1 0;
BA_ "GenSigSendType" SG_ 1540 MHU_DiagRespData2 0;
BA_ "GenSigSendType" SG_ 1540 MHU_DiagRespData3 0;
BA_ "GenSigSendType" SG_ 1540 MHU_DiagRespData4 0;
BA_ "GenSigSendType" SG_ 1540 MHU_DiagRespData5 0;
BA_ "GenSigSendType" SG_ 1540 MHU_DiagRespData6 0;
BA_ "GenSigSendType" SG_ 1540 MHU_DiagRespData7 0;
BA_ "GenSigSendType" SG_ 1667 IPC_DiagReqData0 0;
BA_ "GenSigSendType" SG_ 1667 IPC_DiagReqData1 0;
BA_ "GenSigSendType" SG_ 1667 IPC_DiagReqData2 0;
BA_ "GenSigSendType" SG_ 1667 IPC_DiagReqData3 0;
BA_ "GenSigSendType" SG_ 1667 IPC_DiagReqData4 0;
BA_ "GenSigSendType" SG_ 1667 IPC_DiagReqData5 0;
BA_ "GenSigSendType" SG_ 1667 IPC_DiagReqData6 0;
BA_ "GenSigSendType" SG_ 1667 IPC_DiagReqData7 0;
BA_ "GenSigSendType" SG_ 1539 IPC_DiagRespData0 0;
BA_ "GenSigSendType" SG_ 1539 IPC_DiagRespData1 0;
BA_ "GenSigSendType" SG_ 1539 IPC_DiagRespData2 0;
BA_ "GenSigSendType" SG_ 1539 IPC_DiagRespData3 0;
BA_ "GenSigSendType" SG_ 1539 IPC_DiagRespData4 0;
BA_ "GenSigSendType" SG_ 1539 IPC_DiagRespData5 0;
BA_ "GenSigSendType" SG_ 1539 IPC_DiagRespData6 0;
BA_ "GenSigSendType" SG_ 1539 IPC_DiagRespData7 0;
BA_ "GenSigSendType" SG_ 1673 CCU_DiagReqData0 0;
BA_ "GenSigSendType" SG_ 1673 CCU_DiagReqData1 0;
BA_ "GenSigSendType" SG_ 1673 CCU_DiagReqData2 0;
BA_ "GenSigSendType" SG_ 1673 CCU_DiagReqData3 0;
BA_ "GenSigSendType" SG_ 1673 CCU_DiagReqData4 0;
BA_ "GenSigSendType" SG_ 1673 CCU_DiagReqData5 0;
BA_ "GenSigSendType" SG_ 1673 CCU_DiagReqData6 0;
BA_ "GenSigSendType" SG_ 1673 CCU_DiagReqData7 0;
BA_ "GenSigSendType" SG_ 1545 CCU_DiagRespData0 0;
BA_ "GenSigSendType" SG_ 1545 CCU_DiagRespData1 0;
BA_ "GenSigSendType" SG_ 1545 CCU_DiagRespData2 0;
BA_ "GenSigSendType" SG_ 1545 CCU_DiagRespData3 0;
BA_ "GenSigSendType" SG_ 1545 CCU_DiagRespData4 0;
BA_ "GenSigSendType" SG_ 1545 CCU_DiagRespData5 0;
BA_ "GenSigSendType" SG_ 1545 CCU_DiagRespData6 0;
BA_ "GenSigSendType" SG_ 1545 CCU_DiagRespData7 0;
BA_ "GenSigSendType" SG_ 1666 XGW_DiagReqData0 0;
BA_ "GenSigSendType" SG_ 1666 XGW_DiagReqData1 0;
BA_ "GenSigSendType" SG_ 1666 XGW_DiagReqData2 0;
BA_ "GenSigSendType" SG_ 1666 XGW_DiagReqData3 0;
BA_ "GenSigSendType" SG_ 1666 XGW_DiagReqData4 0;
BA_ "GenSigSendType" SG_ 1666 XGW_DiagReqData5 0;
BA_ "GenSigSendType" SG_ 1666 XGW_DiagReqData6 0;
BA_ "GenSigSendType" SG_ 1666 XGW_DiagReqData7 0;
BA_ "GenSigSendType" SG_ 1538 XGW_DiagRespData0 0;
BA_ "GenSigSendType" SG_ 1538 XGW_DiagRespData1 0;
BA_ "GenSigSendType" SG_ 1538 XGW_DiagRespData2 0;
BA_ "GenSigSendType" SG_ 1538 XGW_DiagRespData3 0;
BA_ "GenSigSendType" SG_ 1538 XGW_DiagRespData4 0;
BA_ "GenSigSendType" SG_ 1538 XGW_DiagRespData5 0;
BA_ "GenSigSendType" SG_ 1538 XGW_DiagRespData6 0;
BA_ "GenSigSendType" SG_ 1538 XGW_DiagRespData7 0;
BA_ "GenSigSendType" SG_ 1706 AVAS_DiagReqData0 0;
BA_ "GenSigSendType" SG_ 1706 AVAS_DiagReqData1 0;
BA_ "GenSigSendType" SG_ 1706 AVAS_DiagReqData2 0;
BA_ "GenSigSendType" SG_ 1706 AVAS_DiagReqData3 0;
BA_ "GenSigSendType" SG_ 1706 AVAS_DiagReqData4 0;
BA_ "GenSigSendType" SG_ 1706 AVAS_DiagReqData5 0;
BA_ "GenSigSendType" SG_ 1706 AVAS_DiagReqData6 0;
BA_ "GenSigSendType" SG_ 1706 AVAS_DiagReqData7 0;
BA_ "GenSigSendType" SG_ 1578 AVAS_DiagRespData0 0;
BA_ "GenSigSendType" SG_ 1578 AVAS_DiagRespData1 0;
BA_ "GenSigSendType" SG_ 1578 AVAS_DiagRespData2 0;
BA_ "GenSigSendType" SG_ 1578 AVAS_DiagRespData3 0;
BA_ "GenSigSendType" SG_ 1578 AVAS_DiagRespData4 0;
BA_ "GenSigSendType" SG_ 1578 AVAS_DiagRespData5 0;
BA_ "GenSigSendType" SG_ 1578 AVAS_DiagRespData6 0;
BA_ "GenSigSendType" SG_ 1578 AVAS_DiagRespData7 0;
BA_ "GenSigSendType" SG_ 1791 GW_DiagFunctionalAddressingData0 0;
BA_ "GenSigSendType" SG_ 1791 GW_DiagFunctionalAddressingData1 0;
BA_ "GenSigSendType" SG_ 1791 GW_DiagFunctionalAddressingData2 0;
BA_ "GenSigSendType" SG_ 1791 GW_DiagFunctionalAddressingData3 0;
BA_ "GenSigSendType" SG_ 1791 GW_DiagFunctionalAddressingData4 0;
BA_ "GenSigSendType" SG_ 1791 GW_DiagFunctionalAddressingData5 0;
BA_ "GenSigSendType" SG_ 1791 GW_DiagFunctionalAddressingData6 0;
BA_ "GenSigSendType" SG_ 1791 GW_DiagFunctionalAddressingData7 0;
